// *************************************************************************** *
// *                                                                           *
// *                      Mentor Graphics Corporation                          *
// *                          All rights reserved                              *
// *                                                                           *
// *************************************************************************** *
// *                                                                           *
// * Description:         CANDB File                                           *
// * Generated at:        2021-02-26 13:32                                     *
// * System:              SPA4710_Final2                                       *
// * Variant:             ConfigurationsSPA3AD_prototype                       *
// * Network:             Mid6CANFD                                            *
// *                                                                           *
// *************************************************************************** *
// *                                                                           *
// *             THIS CONFIGURATION MIGHT CONTAIN SOME ERRORS                  *
// *              IF THE INPUT MODEL WAS NOT PROPERLY FORMED!                  *
// *                    Do Not Use this File directly!                         *
// *                                                                           *
// *************************************************************************** *
VERSION "Mid6CANFD"

NS_ :

BS_ :

BU_ :  ETC SSMB VIMB

BO_ 1292 SsmbMid6CanFdCanNmFr : 8 SSMB
 SG_ Body_SSMB : 21|1@0+ (1,0) [0|0] "" VIMB
 SG_ Brake_SSMB : 33|1@0+ (1,0) [0|0] "" VIMB
 SG_ Diesel_SSMB : 32|1@0+ (1,0) [0|0] "" VIMB
 SG_ Hazard_SSMB : 18|1@0+ (1,0) [0|0] "" VIMB
 SG_ InfotainmentAndHMI_SSMB : 22|1@0+ (1,0) [0|0] "" VIMB
 SG_ PNCCharging_SSMB : 25|1@0+ (1,0) [0|0] "" VIMB
 SG_ PNCDriverinfo_SSMB : 16|1@0+ (1,0) [0|0] "" VIMB
 SG_ PNCDriverinfoPoll_SSMB : 31|1@0+ (1,0) [0|0] "" VIMB
 SG_ PNCDriving_SSMB : 27|1@0+ (1,0) [0|0] "" VIMB
 SG_ PNCEntrance_SSMB : 23|1@0+ (1,0) [0|0] "" VIMB
 SG_ PNCGlobal_SSMB : 29|1@0+ (1,0) [0|0] "" VIMB
 SG_ PNCGSD_SSMB : 30|1@0+ (1,0) [0|0] "" VIMB
 SG_ PNCHVEnergyStorage_SSMB : 35|1@0+ (1,0) [0|0] "" VIMB
 SG_ PNCLocking_SSMB : 17|1@0+ (1,0) [0|0] "" VIMB
 SG_ PNCPreClimatization_SSMB : 26|1@0+ (1,0) [0|0] "" VIMB
 SG_ PNCSpare1_SSMB : 39|1@0+ (1,0) [0|0] "" VIMB
 SG_ PNCSpare2_SSMB : 38|1@0+ (1,0) [0|0] "" VIMB
 SG_ PNCSpare3_SSMB : 37|1@0+ (1,0) [0|0] "" VIMB
 SG_ PNCSpare4_SSMB : 36|1@0+ (1,0) [0|0] "" VIMB
 SG_ PNCStart_SSMB : 24|1@0+ (1,0) [0|0] "" VIMB
 SG_ PNCTrailerCaravan_SSMB : 28|1@0+ (1,0) [0|0] "" VIMB
 SG_ VehicleAPI_SSMB : 34|1@0+ (1,0) [0|0] "" VIMB
 SG_ Visibility_SSMB : 20|1@0+ (1,0) [0|0] "" VIMB
 SG_ WarningSounds_SSMB : 19|1@0+ (1,0) [0|0] "" VIMB
 SG_ NM_PNI_SSMB : 14|1@0+ (1,0) [0|0] "" VIMB
 SG_ NM_AW_SSMB : 12|1@0+ (1,0) [0|0] "" VIMB
 SG_ NM_CS_SSMB : 11|1@0+ (1,0) [0|0] "" VIMB
 SG_ NM_RMR_SSMB : 8|1@0+ (1,0) [0|0] "" VIMB
 SG_ NM_NodeID_SSMB : 7|8@0+ (1,0) [0|0] "" VIMB

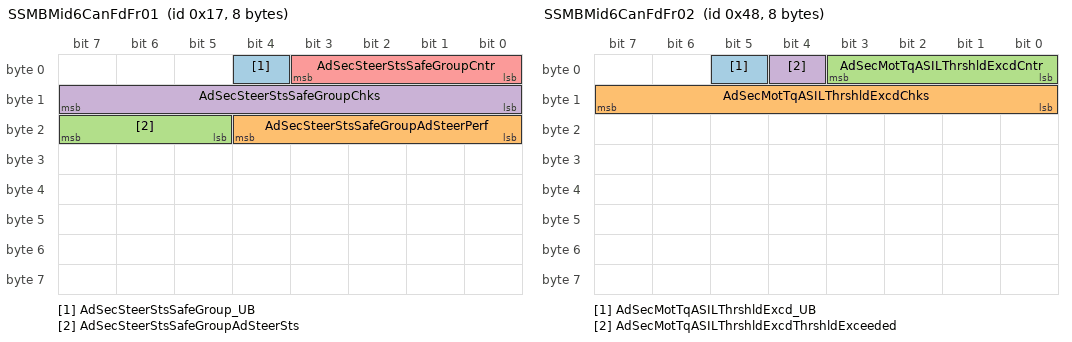
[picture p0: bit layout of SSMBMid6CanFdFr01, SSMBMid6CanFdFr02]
BO_ 23 SSMBMid6CanFdFr01 : 8 SSMB
 SG_ AdSecSteerStsSafeGroup_UB : 4|1@0+ (1,0) [0|1] "" VIMB
 SG_ AdSecSteerStsSafeGroupAdSteerPerf : 20|5@0+ (1,0) [0|31] "" VIMB
 SG_ AdSecSteerStsSafeGroupAdSteerSts : 23|3@0+ (1,0) [0|7] "" VIMB
 SG_ AdSecSteerStsSafeGroupChks : 15|8@0+ (1.0,0.0) [0.0|255.0] "Unitless" VIMB
 SG_ AdSecSteerStsSafeGroupCntr : 3|4@0+ (1.0,0.0) [0.0|15.0] "Unitless" VIMB

BO_ 72 SSMBMid6CanFdFr02 : 8 SSMB
 SG_ AdSecMotTqASILThrshldExcd_UB : 5|1@0+ (1,0) [0|1] "" VIMB
 SG_ AdSecMotTqASILThrshldExcdChks : 15|8@0+ (1.0,0.0) [0.0|255.0] "Unitless" VIMB
 SG_ AdSecMotTqASILThrshldExcdCntr : 3|4@0+ (1.0,0.0) [0.0|15.0] "Unitless" VIMB
 SG_ AdSecMotTqASILThrshldExcdThrshldExceeded : 4|1@0+ (1,0) [0|1] "" VIMB

BO_ 259 SSMBMid6CanFdFr03 : 16 SSMB
 SG_ SecPoseMonSafe_UB : 22|1@0+ (1,0) [0|1] "" VIMB
 SG_ SecPoseMonSafeChks : 31|8@0+ (1.0,0.0) [0.0|255.0] "Unitless" VIMB
 SG_ SecPoseMonSafeCntr : 19|4@0+ (1.0,0.0) [0.0|15.0] "Unitless" VIMB
 SG_ SecPoseMonSafeLatErr : 47|10@0- (0.005,0.0) [-2.56|2.555] "m" VIMB
 SG_ SecPoseMonSafeLgtErr : 53|11@0- (0.005,0.0) [-5.12|5.115] "m" VIMB
 SG_ SecPoseMonSafeSafeQf : 21|2@0+ (1,0) [0|3] "" VIMB
 SG_ SecPoseMonSafeYawErr : 39|8@0- (0.001,0.0) [-0.128|0.127] "rad" VIMB
 SG_ SecSteerMotTq_UB : 23|1@0+ (1,0) [0|1] "" VIMB
 SG_ SecSteerMotTqSteerMotTq : 5|14@0- (0.00390625,0.0) [-30.0|30.0] "NewtonMeter" VIMB
 SG_ SecSteerMotTqSteerMotTqQf : 7|2@0+ (1,0) [0|3] "" VIMB
 SG_ SecWhlLockSts_UB : 58|1@0+ (1,0) [0|1] "" VIMB
 SG_ SecWhlLockStsChks : 79|8@0+ (1.0,0.0) [0.0|255.0] "Unitless" VIMB
 SG_ SecWhlLockStsCntr : 67|4@0+ (1.0,0.0) [0.0|15.0] "Unitless" VIMB
 SG_ SecWhlLockStsDegradedSts : 57|2@0+ (1,0) [0|3] "" VIMB
 SG_ SecWhlLockStsLockSts : 70|3@0+ (1,0) [0|7] "" VIMB
 SG_ SSMBDegraded_UB : 103|1@0+ (1,0) [0|1] "" VIMB
 SG_ SSMBDegradedchks : 95|8@0+ (1.0,0.0) [0.0|255.0] "Unitless" VIMB
 SG_ SSMBDegradedcntr : 83|4@0+ (1.0,0.0) [0.0|15.0] "Unitless" VIMB
 SG_ SSMBDegradedSSMBDegraded : 87|4@0+ (1,0) [0|15] "" VIMB

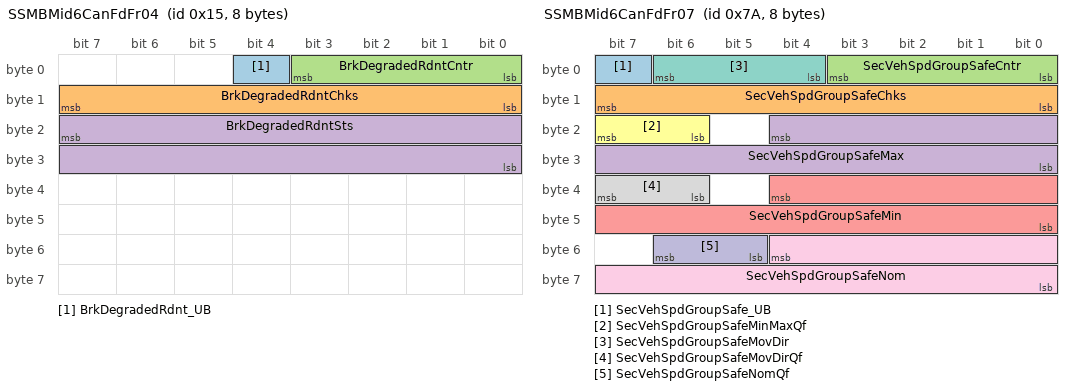
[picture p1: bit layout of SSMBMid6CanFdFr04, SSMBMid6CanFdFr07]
BO_ 21 SSMBMid6CanFdFr04 : 8 SSMB
 SG_ BrkDegradedRdnt_UB : 4|1@0+ (1,0) [0|1] "" VIMB
 SG_ BrkDegradedRdntChks : 15|8@0+ (1.0,0.0) [0.0|255.0] "Unitless" VIMB
 SG_ BrkDegradedRdntCntr : 3|4@0+ (1.0,0.0) [0.0|15.0] "Unitless" VIMB
 SG_ BrkDegradedRdntSts : 23|16@0+ (1.0,0.0) [0.0|65535.0] "Unitless" VIMB

BO_ 32 SSMBMid6CanFdFr05 : 16 SSMB
 SG_ AdSecWhlAgEstimdGroupSafe_UB : 4|1@0+ (1,0) [0|1] "" VIMB
 SG_ AdSecWhlAgEstimdGroupSafeChks : 15|8@0+ (1.0,0.0) [0.0|255.0] "Unitless" VIMB
 SG_ AdSecWhlAgEstimdGroupSafeCntr : 3|4@0+ (1.0,0.0) [0.0|15.0] "Unitless" VIMB
 SG_ AdSecWhlAgEstimdGroupSafeQf1 : 55|2@0+ (1,0) [0|3] "" VIMB
 SG_ AdSecWhlAgEstimdGroupSafeWhlAg : 22|15@0+ (0.00005249,-0.85) [-0.85|0.8500461200000001] "rad" VIMB
 SG_ AdSecWhlAgEstimdGroupSafeWhlAgRate : 38|15@0+ (0.00005,-0.7) [-0.7|0.7000000000000002] "rad/s" VIMB
 SG_ SecWhlRotToothCntr_UB : 52|1@0+ (1,0) [0|1] "" VIMB
 SG_ SecWhlRotToothCntrChks : 63|8@0+ (1.0,0.0) [0.0|255.0] "Unitless" VIMB
 SG_ SecWhlRotToothCntrCntr : 51|4@0+ (1.0,0.0) [0.0|15.0] "Unitless" VIMB
 SG_ SecWhlRotToothCntrWhlRotToothCntrFrntLe : 71|8@0+ (1.0,0.0) [0.0|255.0] "Unitless" VIMB
 SG_ SecWhlRotToothCntrWhlRotToothCntrFrntLeQf : 79|2@0+ (1,0) [0|3] "" VIMB
 SG_ SecWhlRotToothCntrWhlRotToothCntrFrntRi : 87|8@0+ (1.0,0.0) [0.0|255.0] "Unitless" VIMB
 SG_ SecWhlRotToothCntrWhlRotToothCntrFrntRiQf : 77|2@0+ (1,0) [0|3] "" VIMB
 SG_ SecWhlRotToothCntrWhlRotToothCntrReLe : 95|8@0+ (1.0,0.0) [0.0|255.0] "Unitless" VIMB
 SG_ SecWhlRotToothCntrWhlRotToothCntrReLeQf : 75|2@0+ (1,0) [0|3] "" VIMB
 SG_ SecWhlRotToothCntrWhlRotToothCntrReRi : 103|8@0+ (1.0,0.0) [0.0|255.0] "Unitless" VIMB
 SG_ SecWhlRotToothCntrWhlRotToothCntrReRiQf : 73|2@0+ (1,0) [0|3] "" VIMB

BO_ 49 SSMBMid6CanFdFr06 : 64 SSMB
 SG_ SecALatDataRawSafe_UB : 7|1@0+ (1,0) [0|1] "" VIMB
 SG_ SecALatDataRawSafeChks : 15|8@0+ (1.0,0.0) [0.0|255.0] "Unitless" VIMB
 SG_ SecALatDataRawSafeCntr : 3|4@0+ (1.0,0.0) [0.0|15.0] "Unitless" VIMB
 SG_ SecALatDataRawSafeMax : 23|15@0+ (0.001,-16.384) [-16.384|16.383000000000003] "m/s^2" VIMB
 SG_ SecALatDataRawSafeMin : 39|15@0+ (0.001,-16.384) [-16.384|16.383000000000003] "m/s^2" VIMB
 SG_ SecALatDataRawSafeMinMaxQf : 6|2@0+ (1,0) [0|3] "" VIMB
 SG_ SecALatDataRawSafeNom : 55|15@0+ (0.001,-16.384) [-16.384|16.383000000000003] "m/s^2" VIMB
 SG_ SecALatDataRawSafeNomQf : 71|2@0+ (1,0) [0|3] "" VIMB
 SG_ SecALgtDataRawSafe_UB : 196|1@0+ (1,0) [0|1] "" VIMB
 SG_ SecALgtDataRawSafeChks : 79|8@0+ (1.0,0.0) [0.0|255.0] "Unitless" VIMB
 SG_ SecALgtDataRawSafeCntr : 67|4@0+ (1.0,0.0) [0.0|15.0] "Unitless" VIMB
 SG_ SecALgtDataRawSafeMax : 86|15@0+ (0.001,-16.384) [-16.384|16.383000000000003] "m/s^2" VIMB
 SG_ SecALgtDataRawSafeMin : 102|15@0+ (0.001,-16.384) [-16.384|16.383000000000003] "m/s^2" VIMB
 SG_ SecALgtDataRawSafeMinMaxQf : 135|2@0+ (1,0) [0|3] "" VIMB
 SG_ SecALgtDataRawSafeNom : 118|15@0+ (0.001,-16.384) [-16.384|16.383000000000003] "m/s^2" VIMB
 SG_ SecALgtDataRawSafeNomQf : 69|2@0+ (1,0) [0|3] "" VIMB
 SG_ SecAxleSlipStsAndRelAg_UB : 199|1@0+ (1,0) [0|1] "" VIMB
 SG_ SecAxleSlipStsAndRelAgFrntAxle : 223|2@0+ (1,0) [0|3] "" VIMB
 SG_ SecAxleSlipStsAndRelAgIntvSts : 263|2@0+ (1,0) [0|3] "" VIMB
 SG_ SecAxleSlipStsAndRelAgReAxle : 221|2@0+ (1,0) [0|3] "" VIMB
 SG_ SecAxleSlipStsAndRelAgRelPitch : 231|16@0- (0.00005,0.0) [-1.6384|1.6383] "rad" VIMB
 SG_ SecAxleSlipStsAndRelAgRelPitchQf : 219|2@0+ (1,0) [0|3] "" VIMB
 SG_ SecAxleSlipStsAndRelAgRelRoll : 247|16@0- (0.00005,0.0) [-1.6384|1.6383] "rad" VIMB
 SG_ SecAxleSlipStsAndRelAgRelRolQf : 217|2@0+ (1,0) [0|3] "" VIMB
 SG_ SecVLatSafe_UB : 260|1@0+ (1,0) [0|1] "" VIMB
 SG_ SecVLatSafeChks : 279|8@0+ (1.0,0.0) [0.0|255.0] "Unitless" VIMB
 SG_ SecVLatSafeCntr : 259|4@0+ (1.0,0.0) [0.0|15.0] "Unitless" VIMB
 SG_ SecVLatSafeMax : 286|15@0- (0.001,0.0) [-16.384|16.383] "m/s" VIMB
 SG_ SecVLatSafeMin : 302|15@0- (0.001,0.0) [-16.384|16.383] "m/s" VIMB
 SG_ SecVLatSafeMinMaxQf : 266|2@0+ (1,0) [0|3] "" VIMB
 SG_ SecVLatSafeNom : 318|15@0- (0.001,0.0) [-16.384|16.383] "m/s" VIMB
 SG_ SecVLatSafeNomQf : 268|2@0+ (1,0) [0|3] "" VIMB
 SG_ SecWhlRotDirReSafe_UB : 198|1@0+ (1,0) [0|1] "" VIMB
 SG_ SecWhlRotDirReSafeChks : 215|8@0+ (1.0,0.0) [0.0|255.0] "Unitless" VIMB
 SG_ SecWhlRotDirReSafeCntr : 195|4@0+ (1.0,0.0) [0.0|15.0] "Unitless" VIMB
 SG_ SecWhlRotDirReSafeLe : 207|2@0+ (1,0) [0|3] "" VIMB
 SG_ SecWhlRotDirReSafeLeQf : 205|2@0+ (1,0) [0|3] "" VIMB
 SG_ SecWhlRotDirReSafeRi : 203|2@0+ (1,0) [0|3] "" VIMB
 SG_ SecWhlRotDirReSafeRiQf : 201|2@0+ (1,0) [0|3] "" VIMB
 SG_ SecYawRateSafe_UB : 330|1@0+ (1,0) [0|1] "" VIMB
 SG_ SecYawRateSafeChks : 351|8@0+ (1.0,0.0) [0.0|255.0] "Unitless" VIMB
 SG_ SecYawRateSafeCntr : 339|4@0+ (1.0,0.0) [0.0|15.0] "Unitless" VIMB
 SG_ SecYawRateSafeMax : 358|15@0- (0.0002,0.0) [-3.2768|3.2766] "rad/s" VIMB
 SG_ SecYawRateSafeMin : 374|15@0- (0.0002,0.0) [-3.2768|3.2766] "rad/s" VIMB
 SG_ SecYawRateSafeMinMaxQf : 342|2@0+ (1,0) [0|3] "" VIMB
 SG_ SecYawRateSafeNom : 390|15@0- (0.0002,0.0) [-3.2768|3.2766] "rad/s" VIMB
 SG_ SecYawRateSafeNomQf : 329|2@0+ (1,0) [0|3] "" VIMB

BO_ 122 SSMBMid6CanFdFr07 : 8 SSMB
 SG_ SecVehSpdGroupSafe_UB : 7|1@0+ (1,0) [0|1] "" VIMB
 SG_ SecVehSpdGroupSafeChks : 15|8@0+ (1.0,0.0) [0.0|255.0] "Unitless" VIMB
 SG_ SecVehSpdGroupSafeCntr : 3|4@0+ (1.0,0.0) [0.0|15.0] "Unitless" VIMB
 SG_ SecVehSpdGroupSafeMax : 20|13@0+ (0.01,0.0) [0.0|81.91] "m/s" VIMB
 SG_ SecVehSpdGroupSafeMin : 36|13@0+ (0.01,0.0) [0.0|81.91] "m/s" VIMB
 SG_ SecVehSpdGroupSafeMinMaxQf : 23|2@0+ (1,0) [0|3] "" VIMB
 SG_ SecVehSpdGroupSafeMovDir : 6|3@0+ (1,0) [0|7] "" VIMB
 SG_ SecVehSpdGroupSafeMovDirQf : 39|2@0+ (1,0) [0|3] "" VIMB
 SG_ SecVehSpdGroupSafeNom : 52|13@0+ (0.01,0.0) [0.0|81.91] "m/s" VIMB
 SG_ SecVehSpdGroupSafeNomQf : 54|2@0+ (1,0) [0|3] "" VIMB

BO_ 52 SSMBMid6CanFdFr08 : 20 SSMB
 SG_ SecVehMSafe_UB : 141|1@0+ (1,0) [0|1] "" VIMB
 SG_ SecVehMSafeChks : 135|8@0+ (1.0,0.0) [0.0|255.0] "Unitless" VIMB
 SG_ SecVehMSafeCntr : 99|4@0+ (1.0,0.0) [0.0|15.0] "Unitless" VIMB
 SG_ SecVehMSafeNomQf : 101|2@0+ (1,0) [0|3] "" VIMB
 SG_ SecVehMSafeSafeQf : 143|2@0+ (1,0) [0|3] "" VIMB
 SG_ SecVehMSafeVehMMax : 111|8@0+ (5.0,2400.0) [2400.0|3675.0] "kg" VIMB
 SG_ SecVehMSafeVehMMin : 119|8@0+ (5.0,2400.0) [2400.0|3675.0] "kg" VIMB
 SG_ SecVehMSafeVehMNom : 127|8@0+ (5.0,2400.0) [2400.0|3675.0] "kg" VIMB
 SG_ SecWhlAgSpdFrntSafe_UB : 103|1@0+ (1,0) [0|1] "" VIMB
 SG_ SecWhlAgSpdFrntSafeChks : 15|8@0+ (1.0,0.0) [0.0|255.0] "Unitless" VIMB
 SG_ SecWhlAgSpdFrntSafeCntr : 3|4@0+ (1.0,0.0) [0.0|15.0] "Unitless" VIMB
 SG_ SecWhlAgSpdFrntSafeLe : 23|16@0- (0.0078125,0.0) [-255.0|255.0] "rad/s" VIMB
 SG_ SecWhlAgSpdFrntSafeLeQf : 5|2@0+ (1,0) [0|3] "" VIMB
 SG_ SecWhlAgSpdFrntSafeRi : 39|16@0- (0.0078125,0.0) [-255.0|255.0] "rad/s" VIMB
 SG_ SecWhlAgSpdFrntSafeRiQf : 7|2@0+ (1,0) [0|3] "" VIMB
 SG_ SecWhlAgSpdReSafe_UB : 102|1@0+ (1,0) [0|1] "" VIMB
 SG_ SecWhlAgSpdReSafeChks : 63|8@0+ (1.0,0.0) [0.0|255.0] "Unitless" VIMB
 SG_ SecWhlAgSpdReSafeCntr : 51|4@0+ (1.0,0.0) [0.0|15.0] "Unitless" VIMB
 SG_ SecWhlAgSpdReSafeLe : 71|16@0- (0.0078125,0.0) [-255.0|255.0] "rad/s" VIMB
 SG_ SecWhlAgSpdReSafeLeQf : 53|2@0+ (1,0) [0|3] "" VIMB
 SG_ SecWhlAgSpdReSafeRi : 87|16@0- (0.0078125,0.0) [-255.0|255.0] "rad/s" VIMB
 SG_ SecWhlAgSpdReSafeRiQf : 55|2@0+ (1,0) [0|3] "" VIMB

BO_ 85 SSMBMid6CanFdFr11 : 20 SSMB
 SG_ AdSecSafeStopActvGroupSafe_UB : 21|1@0+ (1,0) [0|1] "" VIMB
 SG_ AdSecSafeStopActvGroupSafeChks : 31|8@0+ (1.0,0.0) [0.0|255.0] "Unitless" VIMB
 SG_ AdSecSafeStopActvGroupSafeCntr : 19|4@0+ (1.0,0.0) [0.0|15.0] "Unitless" VIMB
 SG_ AdSecSafeStopActvGroupSafePlatformSafeStopActv : 20|1@0+ (1,0) [0|1] "" VIMB
 SG_ AdSecWhlAgRateLimEstimdSafe_UB : 22|1@0+ (1,0) [0|1] "" VIMB
 SG_ AdSecWhlAgRateLimEstimdSafeAdWhlAgRate1 : 86|15@0+ (0.00005,-0.7) [-0.7|0.7000000000000002] "rad/s" VIMB
 SG_ AdSecWhlAgRateLimEstimdSafeChks : 79|8@0+ (1.0,0.0) [0.0|255.0] "Unitless" VIMB
 SG_ AdSecWhlAgRateLimEstimdSafeCntr : 67|4@0+ (1.0,0.0) [0.0|15.0] "Unitless" VIMB
 SG_ SecMaxALatEstimdGroup_UB : 39|1@0+ (1,0) [0|1] "" VIMB
 SG_ SecMaxALatEstimdGroupAcceleration : 38|15@0- (0.0085,0.0) [-138.99200000000002|139.00050000000002] "m/s^2" VIMB
 SG_ SecMaxALatEstimdGroupJerk : 54|15@0- (0.000244140625,0.0) [-4.0|3.999755859375] "Unitless" VIMB

BO_ 1290 VimbMid6CanFdCanNmFr : 8 VIMB
 SG_ Body_VIMB : 21|1@0+ (1,0) [0|0] "" SSMB
 SG_ Brake_VIMB : 33|1@0+ (1,0) [0|0] "" SSMB
 SG_ Diesel_VIMB : 32|1@0+ (1,0) [0|0] "" SSMB
 SG_ Hazard_VIMB : 18|1@0+ (1,0) [0|0] "" SSMB
 SG_ InfotainmentAndHMI_VIMB : 22|1@0+ (1,0) [0|0] "" SSMB
 SG_ PNCCharging_VIMB : 25|1@0+ (1,0) [0|0] "" SSMB
 SG_ PNCDriverinfo_VIMB : 16|1@0+ (1,0) [0|0] "" SSMB
 SG_ PNCDriverinfoPoll_VIMB : 31|1@0+ (1,0) [0|0] "" SSMB
 SG_ PNCDriving_VIMB : 27|1@0+ (1,0) [0|0] "" SSMB
 SG_ PNCEntrance_VIMB : 23|1@0+ (1,0) [0|0] "" SSMB
 SG_ PNCGlobal_VIMB : 29|1@0+ (1,0) [0|0] "" SSMB
 SG_ PNCGSD_VIMB : 30|1@0+ (1,0) [0|0] "" SSMB
 SG_ PNCHVEnergyStorage_VIMB : 35|1@0+ (1,0) [0|0] "" SSMB
 SG_ PNCLocking_VIMB : 17|1@0+ (1,0) [0|0] "" SSMB
 SG_ PNCPreClimatization_VIMB : 26|1@0+ (1,0) [0|0] "" SSMB
 SG_ PNCSpare1_VIMB : 39|1@0+ (1,0) [0|0] "" SSMB
 SG_ PNCSpare2_VIMB : 38|1@0+ (1,0) [0|0] "" SSMB
 SG_ PNCSpare3_VIMB : 37|1@0+ (1,0) [0|0] "" SSMB
 SG_ PNCSpare4_VIMB : 36|1@0+ (1,0) [0|0] "" SSMB
 SG_ PNCStart_VIMB : 24|1@0+ (1,0) [0|0] "" SSMB
 SG_ PNCTrailerCaravan_VIMB : 28|1@0+ (1,0) [0|0] "" SSMB
 SG_ VehicleAPI_VIMB : 34|1@0+ (1,0) [0|0] "" SSMB
 SG_ Visibility_VIMB : 20|1@0+ (1,0) [0|0] "" SSMB
 SG_ WarningSounds_VIMB : 19|1@0+ (1,0) [0|0] "" SSMB
 SG_ NM_PNI_VIMB : 14|1@0+ (1,0) [0|0] "" SSMB
 SG_ NM_AW_VIMB : 12|1@0+ (1,0) [0|0] "" SSMB
 SG_ NM_CS_VIMB : 11|1@0+ (1,0) [0|0] "" SSMB
 SG_ NM_RMR_VIMB : 8|1@0+ (1,0) [0|0] "" SSMB
 SG_ NM_NodeID_VIMB : 7|8@0+ (1,0) [0|0] "" SSMB

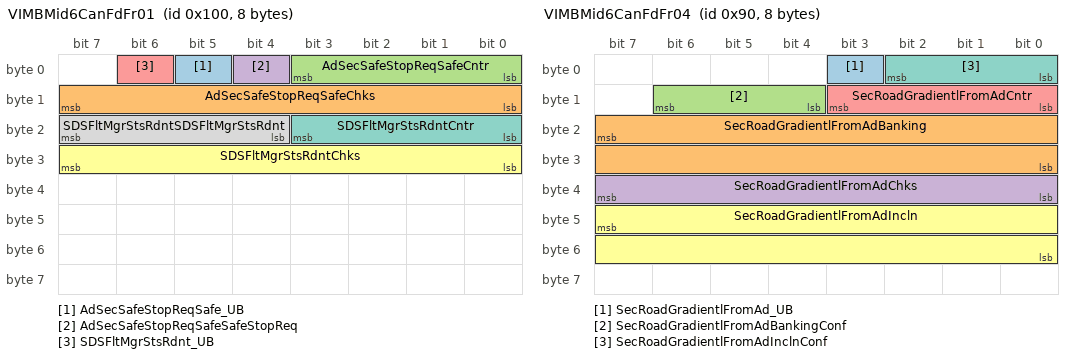
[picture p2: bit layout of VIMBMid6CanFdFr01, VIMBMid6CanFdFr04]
BO_ 256 VIMBMid6CanFdFr01 : 8 VIMB
 SG_ AdSecSafeStopReqSafe_UB : 5|1@0+ (1,0) [0|1] "" SSMB
 SG_ AdSecSafeStopReqSafeChks : 15|8@0+ (1.0,0.0) [0.0|255.0] "Unitless" SSMB
 SG_ AdSecSafeStopReqSafeCntr : 3|4@0+ (1.0,0.0) [0.0|15.0] "Unitless" SSMB
 SG_ AdSecSafeStopReqSafeSafeStopReq : 4|1@0+ (1,0) [0|1] "" SSMB
 SG_ SDSFltMgrStsRdnt_UB : 6|1@0+ (1,0) [0|1] "" SSMB
 SG_ SDSFltMgrStsRdntChks : 31|8@0+ (1.0,0.0) [0.0|255.0] "Unitless" SSMB
 SG_ SDSFltMgrStsRdntCntr : 19|4@0+ (1.0,0.0) [0.0|15.0] "Unitless" SSMB
 SG_ SDSFltMgrStsRdntSDSFltMgrStsRdnt : 23|4@0+ (1,0) [0|15] "" SSMB

BO_ 65 VIMBMid6CanFdFr03 : 64 VIMB
 SG_ AdSecPose_UB : 511|1@0+ (1,0) [0|1] "" SSMB
 SG_ AdSecPoseAX : 24|20@1+ (0.0001,-52.429) [-52.429|52.4285] "m/s^2" SSMB
 SG_ AdSecPoseAXConf : 400|3@1+ (1.0,0.0) [0.0|7.0] "Unitless" SSMB
 SG_ AdSecPoseAY : 48|20@1+ (0.0001,-52.429) [-52.429|52.4285] "m/s^2" SSMB
 SG_ AdSecPoseAYConf : 408|3@1+ (1.0,0.0) [0.0|7.0] "Unitless" SSMB
 SG_ AdSecPoseAZ : 72|20@1+ (0.0001,-52.429) [-52.429|52.4285] "m/s^2" SSMB
 SG_ AdSecPoseAZConf : 416|3@1+ (1.0,0.0) [0.0|7.0] "Unitless" SSMB
 SG_ AdSecPoseChks : 0|16@1+ (1.0,0.0) [0.0|65535.0] "Unitless" SSMB
 SG_ AdSecPoseCntr : 16|8@1+ (1.0,0.0) [0.0|255.0] "Unitless" SSMB
 SG_ AdSecPoseDataID : 96|16@1+ (1.0,0.0) [0.0|65535.0] "Unitless" SSMB
 SG_ AdSecPosePitch : 112|16@1+ (0.00005,-1.638) [-1.638|1.6380000000000003] "rad" SSMB
 SG_ AdSecPosePitchConf : 424|3@1+ (1.0,0.0) [0.0|7.0] "Unitless" SSMB
 SG_ AdSecPosePitchRate : 128|20@1+ (0.00001,-5.243) [-5.243|5.242750000000001] "rad/s" SSMB
 SG_ AdSecPosePitchRateConf : 432|3@1+ (1.0,0.0) [0.0|7.0] "Unitless" SSMB
 SG_ AdSecPosePosX : 152|32@1- (1.0,0.0) [-2147483648.0|2147483647.0] "5mm" SSMB
 SG_ AdSecPosePosXConf : 440|3@1+ (1.0,0.0) [0.0|7.0] "Unitless" SSMB
 SG_ AdSecPosePosY : 184|32@1- (1.0,0.0) [-2147483648.0|2147483647.0] "5mm" SSMB
 SG_ AdSecPosePosYConf : 448|3@1+ (1.0,0.0) [0.0|7.0] "Unitless" SSMB
 SG_ AdSecPoseRoll : 216|16@1+ (0.00005,-1.638) [-1.638|1.6380000000000003] "rad" SSMB
 SG_ AdSecPoseRollConf : 456|3@1+ (1.0,0.0) [0.0|7.0] "Unitless" SSMB
 SG_ AdSecPoseRollRate : 232|20@1+ (0.00001,-5.243) [-5.243|5.242750000000001] "rad/s" SSMB
 SG_ AdSecPoseRollRateConf : 464|3@1+ (1.0,0.0) [0.0|7.0] "Unitless" SSMB
 SG_ AdSecPoseTiStampNanoSec : 256|32@1+ (1.0,0.0) [0.0|4294967295.0] "ns" SSMB
 SG_ AdSecPoseTiStampSec : 288|32@1+ (1.0,0.0) [0.0|4294967295.0] "s" SSMB
 SG_ AdSecPoseVX : 320|16@1+ (0.001,-12.768) [-12.768|52.766999999999996] "m/s" SSMB
 SG_ AdSecPoseVXConf : 472|3@1+ (1.0,0.0) [0.0|7.0] "Unitless" SSMB
 SG_ AdSecPoseVY : 336|14@1+ (0.001,-8.192) [-8.192|8.190999999999999] "m/s" SSMB
 SG_ AdSecPoseVYConf : 480|3@1+ (1.0,0.0) [0.0|7.0] "Unitless" SSMB
 SG_ AdSecPoseYaw : 352|24@1+ (0.0000005,-4.194) [-4.194|4.194] "rad" SSMB
 SG_ AdSecPoseYawConf : 488|3@1+ (1.0,0.0) [0.0|7.0] "Unitless" SSMB
 SG_ AdSecPoseYawRate : 376|22@1+ (0.000001,-2.097) [-2.097|2.097] "rad/s" SSMB
 SG_ AdSecPoseYawRateConf : 496|3@1+ (1.0,0.0) [0.0|7.0] "Unitless" SSMB

BO_ 144 VIMBMid6CanFdFr04 : 8 VIMB
 SG_ SecRoadGradientlFromAd_UB : 3|1@0+ (1,0) [0|1] "" SSMB
 SG_ SecRoadGradientlFromAdBanking : 23|16@0- (0.000030518,0.0) [-0.9999833060000001|0.9999833060000001] "rad" SSMB
 SG_ SecRoadGradientlFromAdBankingConf : 14|3@0+ (1,0) [0|7] "" SSMB
 SG_ SecRoadGradientlFromAdChks : 39|8@0+ (1.0,0.0) [0.0|255.0] "Unitless" SSMB
 SG_ SecRoadGradientlFromAdCntr : 11|4@0+ (1.0,0.0) [0.0|15.0] "Unitless" SSMB
 SG_ SecRoadGradientlFromAdIncln : 47|16@0- (0.000030518,0.0) [-0.9999833060000001|0.9999833060000001] "rad" SSMB
 SG_ SecRoadGradientlFromAdInclnConf : 2|3@0+ (1,0) [0|7] "" SSMB

BO_ 38 VIMBMid6CanFdFr14 : 16 VIMB
 SG_ AdSecWhlAgReqGroupSafe_UB : 4|1@0+ (1,0) [0|1] "" SSMB
 SG_ AdSecWhlAgReqGroupSafeChks : 31|8@0+ (1.0,0.0) [0.0|255.0] "Unitless" SSMB
 SG_ AdSecWhlAgReqGroupSafeCntr : 3|4@0+ (1.0,0.0) [0.0|15.0] "Unitless" SSMB
 SG_ AdSecWhlAgReqGroupSafeWhlAgReq : 14|15@0+ (0.00005249,-0.85) [-0.85|0.8500461200000001] "rad" SSMB

BO_ 272 VIMBMid6CanFdFr19 : 48 VIMB
 SG_ AdSecPSSGroupSafe0_UB : 383|1@0+ (1,0) [0|1] "" SSMB
 SG_ AdSecPSSGroupSafe0Chks : 0|16@1+ (1.0,0.0) [0.0|65535.0] "Unitless" SSMB
 SG_ AdSecPSSGroupSafe0Cntr : 16|8@1+ (1.0,0.0) [0.0|255.0] "Unitless" SSMB
 SG_ AdSecPSSGroupSafe0DataID : 24|16@1+ (1.0,0.0) [0.0|65535.0] "Unitless" SSMB
 SG_ AdSecPSSGroupSafe0DeltaTPos1 : 48|18@1+ (0.000001,0.0) [0.0|0.262] "s" SSMB
 SG_ AdSecPSSGroupSafe0DeltaTPos2 : 72|18@1+ (0.000001,0.0) [0.0|0.262] "s" SSMB
 SG_ AdSecPSSGroupSafe0DeltaXPos1 : 96|18@1+ (0.0001,-13.107) [-13.107|13.107000000000003] "m" SSMB
 SG_ AdSecPSSGroupSafe0DeltaXPos2 : 120|18@1+ (0.0001,-13.107) [-13.107|13.107000000000003] "m" SSMB
 SG_ AdSecPSSGroupSafe0DeltaYPos1 : 144|18@1+ (0.0001,-13.107) [-13.107|13.107000000000003] "m" SSMB
 SG_ AdSecPSSGroupSafe0DeltaYPos2 : 168|18@1+ (0.0001,-13.107) [-13.107|13.107000000000003] "m" SSMB
 SG_ AdSecPSSGroupSafe0HeadingPos1 : 192|16@1+ (0.0001,-3.2767) [-3.2767|3.2768000000000006] "rad" SSMB
 SG_ AdSecPSSGroupSafe0HeadingPos2 : 208|16@1+ (0.0001,-3.2767) [-3.2767|3.2768000000000006] "rad" SSMB
 SG_ AdSecPSSGroupSafe0InitHeading : 224|16@1+ (0.0001,-3.2767) [-3.2767|3.2768000000000006] "rad" SSMB
 SG_ AdSecPSSGroupSafe0InitPosX : 240|32@1- (1.0,0.0) [-2147483648.0|2147483647.0] "m" SSMB
 SG_ AdSecPSSGroupSafe0InitPosY : 272|32@1- (1.0,0.0) [-2147483648.0|2147483647.0] "m" SSMB
 SG_ AdSecPSSGroupSafe0TiStampNanoSec : 304|32@1+ (1.0,0.0) [0.0|4294967295.0] "Unitless" SSMB
 SG_ AdSecPSSGroupSafe0TiStampSec : 336|32@1+ (1.0,0.0) [0.0|4294967295.0] "Unitless" SSMB
 SG_ AdSecPSSGroupSafe0TrajectID : 368|4@1+ (1.0,0.0) [0.0|15.0] "Unitless" SSMB

BO_ 278 VIMBMid6CanFdFr20 : 64 VIMB
 SG_ AdSecPSSGroupSafe1_UB : 511|1@0+ (1,0) [0|1] "" SSMB
 SG_ AdSecPSSGroupSafe1Chks : 0|16@1+ (1.0,0.0) [0.0|65535.0] "Unitless" SSMB
 SG_ AdSecPSSGroupSafe1Cntr : 16|8@1+ (1.0,0.0) [0.0|255.0] "Unitless" SSMB
 SG_ AdSecPSSGroupSafe1DataID : 24|16@1+ (1.0,0.0) [0.0|65535.0] "Unitless" SSMB
 SG_ AdSecPSSGroupSafe1DeltaTPos1 : 40|18@1+ (0.000001,0.0) [0.0|0.262] "s" SSMB
 SG_ AdSecPSSGroupSafe1DeltaTPos2 : 64|18@1+ (0.000001,0.0) [0.0|0.262] "s" SSMB
 SG_ AdSecPSSGroupSafe1DeltaTPos3 : 88|18@1+ (0.000001,0.0) [0.0|0.262] "s" SSMB
 SG_ AdSecPSSGroupSafe1DeltaTPos4 : 112|18@1+ (0.000001,0.0) [0.0|0.262] "s" SSMB
 SG_ AdSecPSSGroupSafe1DeltaTPos5 : 136|18@1+ (0.000001,0.0) [0.0|0.262] "s" SSMB
 SG_ AdSecPSSGroupSafe1DeltaTPos6 : 160|18@1+ (0.000001,0.0) [0.0|0.262] "s" SSMB
 SG_ AdSecPSSGroupSafe1DeltaXPos1 : 184|18@1+ (0.0001,-13.107) [-13.107|13.107000000000003] "m" SSMB
 SG_ AdSecPSSGroupSafe1DeltaXPos2 : 202|18@1+ (0.0001,-13.107) [-13.107|13.107000000000003] "m" SSMB
 SG_ AdSecPSSGroupSafe1DeltaXPos3 : 220|18@1+ (0.0001,-13.107) [-13.107|13.107000000000003] "m" SSMB
 SG_ AdSecPSSGroupSafe1DeltaXPos4 : 238|18@1+ (0.0001,-13.107) [-13.107|13.107000000000003] "m" SSMB
 SG_ AdSecPSSGroupSafe1DeltaXPos5 : 256|18@1+ (0.0001,-13.107) [-13.107|13.107000000000003] "m" SSMB
 SG_ AdSecPSSGroupSafe1DeltaXPos6 : 274|18@1+ (0.0001,-13.107) [-13.107|13.107000000000003] "m" SSMB
 SG_ AdSecPSSGroupSafe1DeltaYPos1 : 292|18@1+ (0.0001,-13.107) [-13.107|13.107000000000003] "m" SSMB
 SG_ AdSecPSSGroupSafe1DeltaYPos2 : 310|18@1+ (0.0001,-13.107) [-13.107|13.107000000000003] "m" SSMB
 SG_ AdSecPSSGroupSafe1DeltaYPos3 : 328|18@1+ (0.0001,-13.107) [-13.107|13.107000000000003] "m" SSMB
 SG_ AdSecPSSGroupSafe1DeltaYPos4 : 346|18@1+ (0.0001,-13.107) [-13.107|13.107000000000003] "m" SSMB
 SG_ AdSecPSSGroupSafe1DeltaYPos5 : 364|18@1+ (0.0001,-13.107) [-13.107|13.107000000000003] "m" SSMB
 SG_ AdSecPSSGroupSafe1DeltaYPos6 : 382|18@1+ (0.0001,-13.107) [-13.107|13.107000000000003] "m" SSMB
 SG_ AdSecPSSGroupSafe1HeadingPos1 : 400|16@1+ (0.0001,-3.2767) [-3.2767|3.2768000000000006] "rad" SSMB
 SG_ AdSecPSSGroupSafe1HeadingPos2 : 416|16@1+ (0.0001,-3.2767) [-3.2767|3.2768000000000006] "rad" SSMB
 SG_ AdSecPSSGroupSafe1HeadingPos3 : 432|16@1+ (0.0001,-3.2767) [-3.2767|3.2768000000000006] "rad" SSMB
 SG_ AdSecPSSGroupSafe1HeadingPos4 : 448|16@1+ (0.0001,-3.2767) [-3.2767|3.2768000000000006] "rad" SSMB
 SG_ AdSecPSSGroupSafe1HeadingPos5 : 464|16@1+ (0.0001,-3.2767) [-3.2767|3.2768000000000006] "rad" SSMB
 SG_ AdSecPSSGroupSafe1HeadingPos6 : 480|16@1+ (0.0001,-3.2767) [-3.2767|3.2768000000000006] "rad" SSMB
 SG_ AdSecPSSGroupSafe1TrajectID : 496|4@1+ (1.0,0.0) [0.0|15.0] "Unitless" SSMB

BO_ 281 VIMBMid6CanFdFr21 : 64 VIMB
 SG_ AdSecPSSGroupSafe2_UB : 511|1@0+ (1,0) [0|1] "" SSMB
 SG_ AdSecPSSGroupSafe2Chks : 0|16@1+ (1.0,0.0) [0.0|65535.0] "Unitless" SSMB
 SG_ AdSecPSSGroupSafe2Cntr : 16|8@1+ (1.0,0.0) [0.0|255.0] "Unitless" SSMB
 SG_ AdSecPSSGroupSafe2DataID : 24|16@1+ (1.0,0.0) [0.0|65535.0] "Unitless" SSMB
 SG_ AdSecPSSGroupSafe2DeltaTPos1 : 40|18@1+ (0.000001,0.0) [0.0|0.262] "s" SSMB
 SG_ AdSecPSSGroupSafe2DeltaTPos2 : 64|18@1+ (0.000001,0.0) [0.0|0.262] "s" SSMB
 SG_ AdSecPSSGroupSafe2DeltaTPos3 : 88|18@1+ (0.000001,0.0) [0.0|0.262] "s" SSMB
 SG_ AdSecPSSGroupSafe2DeltaTPos4 : 112|18@1+ (0.000001,0.0) [0.0|0.262] "s" SSMB
 SG_ AdSecPSSGroupSafe2DeltaTPos5 : 136|18@1+ (0.000001,0.0) [0.0|0.262] "s" SSMB
 SG_ AdSecPSSGroupSafe2DeltaTPos6 : 160|18@1+ (0.000001,0.0) [0.0|0.262] "s" SSMB
 SG_ AdSecPSSGroupSafe2DeltaXPos1 : 184|18@1+ (0.0001,-13.107) [-13.107|13.107000000000003] "m" SSMB
 SG_ AdSecPSSGroupSafe2DeltaXPos2 : 202|18@1+ (0.0001,-13.107) [-13.107|13.107000000000003] "m" SSMB
 SG_ AdSecPSSGroupSafe2DeltaXPos3 : 220|18@1+ (0.0001,-13.107) [-13.107|13.107000000000003] "m" SSMB
 SG_ AdSecPSSGroupSafe2DeltaXPos4 : 238|18@1+ (0.0001,-13.107) [-13.107|13.107000000000003] "m" SSMB
 SG_ AdSecPSSGroupSafe2DeltaXPos5 : 256|18@1+ (0.0001,-13.107) [-13.107|13.107000000000003] "m" SSMB
 SG_ AdSecPSSGroupSafe2DeltaXPos6 : 274|18@1+ (0.0001,-13.107) [-13.107|13.107000000000003] "m" SSMB
 SG_ AdSecPSSGroupSafe2DeltaYPos1 : 292|18@1+ (0.0001,-13.107) [-13.107|13.107000000000003] "m" SSMB
 SG_ AdSecPSSGroupSafe2DeltaYPos2 : 310|18@1+ (0.0001,-13.107) [-13.107|13.107000000000003] "m" SSMB
 SG_ AdSecPSSGroupSafe2DeltaYPos3 : 328|18@1+ (0.0001,-13.107) [-13.107|13.107000000000003] "m" SSMB
 SG_ AdSecPSSGroupSafe2DeltaYPos4 : 346|18@1+ (0.0001,-13.107) [-13.107|13.107000000000003] "m" SSMB
 SG_ AdSecPSSGroupSafe2DeltaYPos5 : 364|18@1+ (0.0001,-13.107) [-13.107|13.107000000000003] "m" SSMB
 SG_ AdSecPSSGroupSafe2DeltaYPos6 : 382|18@1+ (0.0001,-13.107) [-13.107|13.107000000000003] "m" SSMB
 SG_ AdSecPSSGroupSafe2HeadingPos1 : 400|16@1+ (0.0001,-3.2767) [-3.2767|3.2768000000000006] "rad" SSMB
 SG_ AdSecPSSGroupSafe2HeadingPos2 : 416|16@1+ (0.0001,-3.2767) [-3.2767|3.2768000000000006] "rad" SSMB
 SG_ AdSecPSSGroupSafe2HeadingPos3 : 432|16@1+ (0.0001,-3.2767) [-3.2767|3.2768000000000006] "rad" SSMB
 SG_ AdSecPSSGroupSafe2HeadingPos4 : 448|16@1+ (0.0001,-3.2767) [-3.2767|3.2768000000000006] "rad" SSMB
 SG_ AdSecPSSGroupSafe2HeadingPos5 : 464|16@1+ (0.0001,-3.2767) [-3.2767|3.2768000000000006] "rad" SSMB
 SG_ AdSecPSSGroupSafe2HeadingPos6 : 480|16@1+ (0.0001,-3.2767) [-3.2767|3.2768000000000006] "rad" SSMB
 SG_ AdSecPSSGroupSafe2TrajectID : 496|4@1+ (1.0,0.0) [0.0|15.0] "Unitless" SSMB

// Node Comments
CM_ BU_ ETC "External Tester Connector";

// Signal Comments
CM_ SG_ 23 AdSecSteerStsSafeGroupAdSteerPerf " Performance of MotorHalf1 + MotorHalf2";
CM_ SG_ 23 AdSecSteerStsSafeGroupAdSteerSts " Status of steering system";
CM_ SG_ 23 AdSecSteerStsSafeGroupChks " E2E-protection";
CM_ SG_ 23 AdSecSteerStsSafeGroupCntr " E2E-protection";
CM_ SG_ 72 AdSecMotTqASILThrshldExcdChks " E2E protection";
CM_ SG_ 72 AdSecMotTqASILThrshldExcdCntr " E2E protection";
CM_ SG_ 72 AdSecMotTqASILThrshldExcdThrshldExceeded " Boolean stating if the current operation is within the ASIL-D area of the steering system.";
CM_ SG_ 259 SecPoseMonSafeChks "Secondary Pose monitoring Checksum";
CM_ SG_ 259 SecPoseMonSafeCntr "Secondary Pose monitoring Counter";
CM_ SG_ 259 SecPoseMonSafeLatErr "Secondary Pose monitoring Lateral Error";
CM_ SG_ 259 SecPoseMonSafeLgtErr "Secondary Pose monitoring Longitudinal Error";
CM_ SG_ 259 SecPoseMonSafeSafeQf "Secondary Pose monitoring Quality factor for Longitudinal, Lateral and Yaw Error";
CM_ SG_ 259 SecPoseMonSafeYawErr "Secondary Pose monitoring Yaw Error";
CM_ SG_ 259 SecSteerMotTqSteerMotTq " Steering motor torque";
CM_ SG_ 259 SecSteerMotTqSteerMotTqQf " Quality factor for SteerMotTq";
CM_ SG_ 259 SecWhlLockStsChks "Secondary Wheel lock and degradation status Checksum";
CM_ SG_ 259 SecWhlLockStsCntr "Secondary Wheel lock and degradation status Counter";
CM_ SG_ 259 SecWhlLockStsDegradedSts "Secondary Wheel lock and degradation status Wheel Lock degraded status";
CM_ SG_ 259 SecWhlLockStsLockSts "Secondary Wheel lock and degradation status Wheel Lock Status";
CM_ SG_ 259 SSMBDegradedchks " CRC";
CM_ SG_ 259 SSMBDegradedcntr " counter";
CM_ SG_ 259 SSMBDegradedSSMBDegraded " Secondry Channel Degradation";
CM_ SG_ 21 BrkDegradedRdntChks " Checksum";
CM_ SG_ 21 BrkDegradedRdntCntr " Counter";
CM_ SG_ 21 BrkDegradedRdntSts " Brake degraded status";
CM_ SG_ 32 AdSecWhlAgEstimdGroupSafeChks "AD secondary wheel angle feedback E2E Checksum";
CM_ SG_ 32 AdSecWhlAgEstimdGroupSafeCntr "AD secondary wheel angle feedback E2E Counter";
CM_ SG_ 32 AdSecWhlAgEstimdGroupSafeQf1 "AD secondary wheel angle feedback Quality Factor of the rack position¨";
CM_ SG_ 32 AdSecWhlAgEstimdGroupSafeWhlAg "AD secondary wheel angle feedback Wheel angle estimate";
CM_ SG_ 32 AdSecWhlAgEstimdGroupSafeWhlAgRate "AD secondary wheel angle feedback Wheel angle rate estimate.";
CM_ SG_ 32 SecWhlRotToothCntrChks "Added with SCR 515, Vehicle State 519G

WhlRotToothCntrRec signal with Qf. E2E Checksum";
CM_ SG_ 32 SecWhlRotToothCntrCntr "Added with SCR 515, Vehicle State 519G

WhlRotToothCntrRec signal with Qf. E2E Counter";
CM_ SG_ 32 SecWhlRotToothCntrWhlRotToothCntrFrntLe "Added with SCR 515, Vehicle State 519G

WhlRotToothCntrRec signal with Qf. Wheel rotation impulse counter front left. For one complete wheel revolution the counter will increase by 96 (with 48 magnetic pole-pairs)";
CM_ SG_ 32 SecWhlRotToothCntrWhlRotToothCntrFrntLeQf "Added with SCR 515, Vehicle State 519G

WhlRotToothCntrRec signal with Qf. Quality factor for front left wheel";
CM_ SG_ 32 SecWhlRotToothCntrWhlRotToothCntrFrntRi "Added with SCR 515, Vehicle State 519G

WhlRotToothCntrRec signal with Qf. Wheel rotation impulse counter front right. For one complete wheel revolution the counter will increase by 96 (with 48 magnetic pole-pairs)";
CM_ SG_ 32 SecWhlRotToothCntrWhlRotToothCntrFrntRiQf "Added with SCR 515, Vehicle State 519G

WhlRotToothCntrRec signal with Qf. Quality factor for front right wheel";
CM_ SG_ 32 SecWhlRotToothCntrWhlRotToothCntrReLe "Added with SCR 515, Vehicle State 519G

WhlRotToothCntrRec signal with Qf. Wheel rotation impulse counter rear left. For one complete wheel revolution the counter will increase by 96 (with 48 magnetic pole-pairs)";
CM_ SG_ 32 SecWhlRotToothCntrWhlRotToothCntrReLeQf "Added with SCR 515, Vehicle State 519G

WhlRotToothCntrRec signal with Qf. Quality factor for rear left wheel";
CM_ SG_ 32 SecWhlRotToothCntrWhlRotToothCntrReRi "Added with SCR 515, Vehicle State 519G

WhlRotToothCntrRec signal with Qf. Wheel rotation impulse counter Rear right. For one complete wheel revolution the counter will increase by 96 (with 48 magnetic pole-pairs)";
CM_ SG_ 32 SecWhlRotToothCntrWhlRotToothCntrReRiQf "Added with SCR 515, Vehicle State 519G

WhlRotToothCntrRec signal with Qf. Quality factor for rear right wheel";
CM_ SG_ 49 SecALatDataRawSafeChks "Lateral acceleration estimation (Secondary) Checksum";
CM_ SG_ 49 SecALatDataRawSafeCntr "Lateral acceleration estimation (Secondary) Counter";
CM_ SG_ 49 SecALatDataRawSafeMax "Lateral acceleration estimation (Secondary) Maximum Lateral Acceleration";
CM_ SG_ 49 SecALatDataRawSafeMin "Lateral acceleration estimation (Secondary) Minimum Lateral Acceleration";
CM_ SG_ 49 SecALatDataRawSafeMinMaxQf "Lateral acceleration estimation (Secondary) Quality factor for Min and Max signals";
CM_ SG_ 49 SecALatDataRawSafeNom "Lateral acceleration estimation (Secondary) Nominal Lateral Acceleration";
CM_ SG_ 49 SecALatDataRawSafeNomQf "Lateral acceleration estimation (Secondary) Quality factor for Nom signal";
CM_ SG_ 49 SecALgtDataRawSafeChks "Longitudinal acceleration estimation (Secondary) Checksum";
CM_ SG_ 49 SecALgtDataRawSafeCntr "Longitudinal acceleration estimation (Secondary) Counter";
CM_ SG_ 49 SecALgtDataRawSafeMax "Longitudinal acceleration estimation (Secondary) Maximum longitudinal acceleration";
CM_ SG_ 49 SecALgtDataRawSafeMin "Longitudinal acceleration estimation (Secondary) Minimum longitudinal acceleration";
CM_ SG_ 49 SecALgtDataRawSafeMinMaxQf "Longitudinal acceleration estimation (Secondary) Quality factor for Min and Max signals";
CM_ SG_ 49 SecALgtDataRawSafeNom "Longitudinal acceleration estimation (Secondary) Nominal longitudinal acceleration";
CM_ SG_ 49 SecALgtDataRawSafeNomQf "Longitudinal acceleration estimation (Secondary) Quality factor for Nom signal";
CM_ SG_ 49 SecAxleSlipStsAndRelAgFrntAxle "Secondary:
---------
It contains Front and Rear Axle Slip status, Intervention Status and Relative Roll & Pitch informations. Front axle slip status";
CM_ SG_ 49 SecAxleSlipStsAndRelAgIntvSts "Secondary:
---------
It contains Front and Rear Axle Slip status, Intervention Status and Relative Roll & Pitch informations. Intervention status";
CM_ SG_ 49 SecAxleSlipStsAndRelAgReAxle "Secondary:
---------
It contains Front and Rear Axle Slip status, Intervention Status and Relative Roll & Pitch informations. Rear axle slip status";
CM_ SG_ 49 SecAxleSlipStsAndRelAgRelPitch "Secondary:
---------
It contains Front and Rear Axle Slip status, Intervention Status and Relative Roll & Pitch informations. Relative Pitch";
CM_ SG_ 49 SecAxleSlipStsAndRelAgRelPitchQf "Secondary:
---------
It contains Front and Rear Axle Slip status, Intervention Status and Relative Roll & Pitch informations. Qulality Factor of Relative Pitch";
CM_ SG_ 49 SecAxleSlipStsAndRelAgRelRoll "Secondary:
---------
It contains Front and Rear Axle Slip status, Intervention Status and Relative Roll & Pitch informations. Relative Roll";
CM_ SG_ 49 SecAxleSlipStsAndRelAgRelRolQf "Secondary:
---------
It contains Front and Rear Axle Slip status, Intervention Status and Relative Roll & Pitch informations. Qulality Factor of Relative Roll";
CM_ SG_ 49 SecVLatSafeChks "Lateral Velocity estimation (Secondary) Checksum";
CM_ SG_ 49 SecVLatSafeCntr "Lateral Velocity estimation (Secondary) Counter";
CM_ SG_ 49 SecVLatSafeMax "Lateral Velocity estimation (Secondary) Maximum Lateral Velocity";
CM_ SG_ 49 SecVLatSafeMin "Lateral Velocity estimation (Secondary) Minimum Lateral Velocity";
CM_ SG_ 49 SecVLatSafeMinMaxQf "Lateral Velocity estimation (Secondary) Quality factor for Min and Max signals";
CM_ SG_ 49 SecVLatSafeNom "Lateral Velocity estimation (Secondary) Nominal Lateral Velocity";
CM_ SG_ 49 SecVLatSafeNomQf "Lateral Velocity estimation (Secondary) Quality Factor for Nom signal";
CM_ SG_ 49 SecWhlRotDirReSafeChks "Wheel Rotation direction for Rear left and Rear right. E2E checksum";
CM_ SG_ 49 SecWhlRotDirReSafeCntr "Wheel Rotation direction for Rear left and Rear right. E2E Counter";
CM_ SG_ 49 SecWhlRotDirReSafeLe "Wheel Rotation direction for Rear left and Rear right. Left wheel";
CM_ SG_ 49 SecWhlRotDirReSafeLeQf "Wheel Rotation direction for Rear left and Rear right. Qualilty factor of left wheel rotation";
CM_ SG_ 49 SecWhlRotDirReSafeRi "Wheel Rotation direction for Rear left and Rear right. Right wheel";
CM_ SG_ 49 SecWhlRotDirReSafeRiQf "Wheel Rotation direction for Rear left and Rear right. Quality factor of right wheel rotation";
CM_ SG_ 49 SecYawRateSafeChks "Yaw Rate Estimation (Secondary) Checksum";
CM_ SG_ 49 SecYawRateSafeCntr "Yaw Rate Estimation (Secondary) Counter";
CM_ SG_ 49 SecYawRateSafeMax "Yaw Rate Estimation (Secondary) Maximum Yaw Rate";
CM_ SG_ 49 SecYawRateSafeMin "Yaw Rate Estimation (Secondary) Minimum Yaw Rate";
CM_ SG_ 49 SecYawRateSafeMinMaxQf "Yaw Rate Estimation (Secondary) Quality factor for Min and Max signals";
CM_ SG_ 49 SecYawRateSafeNom "Yaw Rate Estimation (Secondary) Nominal Yaw Rate";
CM_ SG_ 49 SecYawRateSafeNomQf "Yaw Rate Estimation (Secondary) Quality factor for Nom signal";
CM_ SG_ 122 SecVehSpdGroupSafeChks "Vehicle speed over ground and Moving direction (Secondary) Checksum";
CM_ SG_ 122 SecVehSpdGroupSafeCntr "Vehicle speed over ground and Moving direction (Secondary) Counter";
CM_ SG_ 122 SecVehSpdGroupSafeMax "Vehicle speed over ground and Moving direction (Secondary) Maximum vehicle speed over ground";
CM_ SG_ 122 SecVehSpdGroupSafeMin "Vehicle speed over ground and Moving direction (Secondary) Minimum vehicle speed over ground";
CM_ SG_ 122 SecVehSpdGroupSafeMinMaxQf "Vehicle speed over ground and Moving direction (Secondary) Quality factor for Min and Max signals";
CM_ SG_ 122 SecVehSpdGroupSafeMovDir "Vehicle speed over ground and Moving direction (Secondary) Actual moving direction";
CM_ SG_ 122 SecVehSpdGroupSafeMovDirQf "Vehicle speed over ground and Moving direction (Secondary) Quality factor for Actual moving direction";
CM_ SG_ 122 SecVehSpdGroupSafeNom "Vehicle speed over ground and Moving direction (Secondary) Nominal vehicle speed over ground";
CM_ SG_ 122 SecVehSpdGroupSafeNomQf "Vehicle speed over ground and Moving direction (Secondary) Quality factor for Nom signal";
CM_ SG_ 52 SecVehMSafeChks "Vehicle Mass estimation E2E Checksum";
CM_ SG_ 52 SecVehMSafeCntr "Vehicle Mass estimation E2E Conter";
CM_ SG_ 52 SecVehMSafeNomQf "Vehicle Mass estimation Vehicle Mass Nominal Quality factor ";
CM_ SG_ 52 SecVehMSafeSafeQf "Vehicle Mass estimation Vehicle Mass Min Max Quality factor ";
CM_ SG_ 52 SecVehMSafeVehMMax "Vehicle Mass estimation Vehicle Mass Maximum Value";
CM_ SG_ 52 SecVehMSafeVehMMin "Vehicle Mass estimation Vehicle Mass Minimum Value";
CM_ SG_ 52 SecVehMSafeVehMNom "Vehicle Mass estimation Vehicle Mass Nominal Value";
CM_ SG_ 52 SecWhlAgSpdFrntSafeChks "Wheel angle speed front wheels, secondary channel

Added with SCR 1972, Vehicle State 519G Checksum";
CM_ SG_ 52 SecWhlAgSpdFrntSafeCntr "Wheel angle speed front wheels, secondary channel

Added with SCR 1972, Vehicle State 519G Counter";
CM_ SG_ 52 SecWhlAgSpdFrntSafeLe "Wheel angle speed front wheels, secondary channel

Added with SCR 1972, Vehicle State 519G Angular velocity of left wheel.";
CM_ SG_ 52 SecWhlAgSpdFrntSafeLeQf "Wheel angle speed front wheels, secondary channel

Added with SCR 1972, Vehicle State 519G Qf for wheel speed sensor";
CM_ SG_ 52 SecWhlAgSpdFrntSafeRi "Wheel angle speed front wheels, secondary channel

Added with SCR 1972, Vehicle State 519G Angular velocity of right wheel.";
CM_ SG_ 52 SecWhlAgSpdFrntSafeRiQf "Wheel angle speed front wheels, secondary channel

Added with SCR 1972, Vehicle State 519G Qf for wheel speed sensor";
CM_ SG_ 52 SecWhlAgSpdReSafeChks "Wheel angle speed rear wheels, secondary channel

Added with SCR 1972, Vehicle State 519G Checksum";
CM_ SG_ 52 SecWhlAgSpdReSafeCntr "Wheel angle speed rear wheels, secondary channel

Added with SCR 1972, Vehicle State 519G Counter";
CM_ SG_ 52 SecWhlAgSpdReSafeLe "Wheel angle speed rear wheels, secondary channel

Added with SCR 1972, Vehicle State 519G Angular velocity of left wheel.";
CM_ SG_ 52 SecWhlAgSpdReSafeLeQf "Wheel angle speed rear wheels, secondary channel

Added with SCR 1972, Vehicle State 519G Qf for wheel speed sensor";
CM_ SG_ 52 SecWhlAgSpdReSafeRi "Wheel angle speed rear wheels, secondary channel

Added with SCR 1972, Vehicle State 519G Angular velocity of right wheel.";
CM_ SG_ 52 SecWhlAgSpdReSafeRiQf "Wheel angle speed rear wheels, secondary channel

Added with SCR 1972, Vehicle State 519G Qf for wheel speed sensor";
CM_ SG_ 85 AdSecSafeStopActvGroupSafeChks "Platform safe stop, secondary channel E2E checksum";
CM_ SG_ 85 AdSecSafeStopActvGroupSafeCntr "Platform safe stop, secondary channel E2E counter";
CM_ SG_ 85 AdSecSafeStopActvGroupSafePlatformSafeStopActv "Platform safe stop, secondary channel Safe stop active";
CM_ SG_ 85 AdSecWhlAgRateLimEstimdSafeAdWhlAgRate1 " Maximum wheel angle rate calculated from limited rack position rate";
CM_ SG_ 85 AdSecWhlAgRateLimEstimdSafeChks " Checksum";
CM_ SG_ 85 AdSecWhlAgRateLimEstimdSafeCntr " Counter";
CM_ SG_ 85 SecMaxALatEstimdGroupAcceleration " Maximum lateral acceleration";
CM_ SG_ 85 SecMaxALatEstimdGroupJerk " Maximum lateral acceleration rate";
CM_ SG_ 256 AdSecSafeStopReqSafeChks "Safe stop request E2E checksum";
CM_ SG_ 256 AdSecSafeStopReqSafeCntr "Safe stop request E2E counter";
CM_ SG_ 256 AdSecSafeStopReqSafeSafeStopReq "Safe stop request Safe stop request";
CM_ SG_ 256 SDSFltMgrStsRdntChks "SDS Fault Manager Status is to communicate the fault status to SSMB (ASIL D) CRC";
CM_ SG_ 256 SDSFltMgrStsRdntCntr "SDS Fault Manager Status is to communicate the fault status to SSMB (ASIL D) Counter";
CM_ SG_ 256 SDSFltMgrStsRdntSDSFltMgrStsRdnt "SDS Fault Manager Status is to communicate the fault status to SSMB (ASIL D)";
CM_ SG_ 65 AdSecPoseAX "POSE information Acceleration X";
CM_ SG_ 65 AdSecPoseAXConf "POSE information Confidence for acceleration X";
CM_ SG_ 65 AdSecPoseAY "POSE information Acceleration Y";
CM_ SG_ 65 AdSecPoseAYConf "POSE information Confidence for acceleration Y";
CM_ SG_ 65 AdSecPoseAZ "POSE information Acceleration Z";
CM_ SG_ 65 AdSecPoseAZConf "POSE information Confidence for acceleration Z";
CM_ SG_ 65 AdSecPoseChks "POSE information E2E profile 5 Check Sum";
CM_ SG_ 65 AdSecPoseCntr "POSE information E2E profile 5 counter";
CM_ SG_ 65 AdSecPoseDataID "POSE information E2E profile 5 Data ID";
CM_ SG_ 65 AdSecPosePitch "POSE information Pitch";
CM_ SG_ 65 AdSecPosePitchConf "POSE information Confidence for pitch";
CM_ SG_ 65 AdSecPosePitchRate "POSE information Pitch rate";
CM_ SG_ 65 AdSecPosePitchRateConf "POSE information Confidence for Pitch rate";
CM_ SG_ 65 AdSecPosePosX "POSE information Position X";
CM_ SG_ 65 AdSecPosePosXConf "POSE information Confidence for position X";
CM_ SG_ 65 AdSecPosePosY "POSE information Position Y";
CM_ SG_ 65 AdSecPosePosYConf "POSE information Confidence for position Y";
CM_ SG_ 65 AdSecPoseRoll "POSE information Roll";
CM_ SG_ 65 AdSecPoseRollConf "POSE information Confidence for Roll";
CM_ SG_ 65 AdSecPoseRollRate "POSE information Roll rate";
CM_ SG_ 65 AdSecPoseRollRateConf "POSE information Confidence for roll rate";
CM_ SG_ 65 AdSecPoseTiStampNanoSec "POSE information Time Stamp Nano Second";
CM_ SG_ 65 AdSecPoseTiStampSec "POSE information Time stampSecond";
CM_ SG_ 65 AdSecPoseVX "POSE information Velocity X";
CM_ SG_ 65 AdSecPoseVXConf "POSE information Confidence for velocity X";
CM_ SG_ 65 AdSecPoseVY "POSE information Velocity Y";
CM_ SG_ 65 AdSecPoseVYConf "POSE information Confidence for velocity Y";
CM_ SG_ 65 AdSecPoseYaw "POSE information Yaw";
CM_ SG_ 65 AdSecPoseYawConf "POSE information Confidence for yaw";
CM_ SG_ 65 AdSecPoseYawRate "POSE information Yaw rate";
CM_ SG_ 65 AdSecPoseYawRateConf "POSE information Confidence for yaw rate";
CM_ SG_ 144 SecRoadGradientlFromAdBanking "Estimated road gradients, secondary channels Road banking";
CM_ SG_ 144 SecRoadGradientlFromAdBankingConf "Estimated road gradients, secondary channels Banking confidence";
CM_ SG_ 144 SecRoadGradientlFromAdChks "Estimated road gradients, secondary channels E2E checksum";
CM_ SG_ 144 SecRoadGradientlFromAdCntr "Estimated road gradients, secondary channels E2E counter";
CM_ SG_ 144 SecRoadGradientlFromAdIncln "Estimated road gradients, secondary channels Road inclination";
CM_ SG_ 144 SecRoadGradientlFromAdInclnConf "Estimated road gradients, secondary channels Inclination confidence";
CM_ SG_ 38 AdSecWhlAgReqGroupSafeChks "AD Requested wheel angle, secondary channel E2E Checksum";
CM_ SG_ 38 AdSecWhlAgReqGroupSafeCntr "AD Requested wheel angle, secondary channel E2E Counter";
CM_ SG_ 38 AdSecWhlAgReqGroupSafeWhlAgReq "AD Requested wheel angle, secondary channel The requested wheel angle. The wheel angle is supervised by the LatCtrl ASIL D supervisory controller before being converted to an ASIL D rack position request.";
CM_ SG_ 272 AdSecPSSGroupSafe0Chks "Platform Safe Stop buffer paths. 

All signalgroups cover 50 points + 1 initial point. Each point has delta X, Y, time and heading. All signal groups are tied together with a trajectory id. 
All signalgroups include signals for E2E protection using profile 5 according to Autosar 4.2.2.

Signal group 0 includes:
* Initial point
* PSS point 1 and 2 E2E checksum, profile 5";
CM_ SG_ 272 AdSecPSSGroupSafe0Cntr "Platform Safe Stop buffer paths. 

All signalgroups cover 50 points + 1 initial point. Each point has delta X, Y, time and heading. All signal groups are tied together with a trajectory id. 
All signalgroups include signals for E2E protection using profile 5 according to Autosar 4.2.2.

Signal group 0 includes:
* Initial point
* PSS point 1 and 2 E2E Counter, profile 5";
CM_ SG_ 272 AdSecPSSGroupSafe0DataID "Platform Safe Stop buffer paths. 

All signalgroups cover 50 points + 1 initial point. Each point has delta X, Y, time and heading. All signal groups are tied together with a trajectory id. 
All signalgroups include signals for E2E protection using profile 5 according to Autosar 4.2.2.

Signal group 0 includes:
* Initial point
* PSS point 1 and 2 E2E Data ID, profile 5";
CM_ SG_ 272 AdSecPSSGroupSafe0DeltaTPos1 "Platform Safe Stop buffer paths. 

All signalgroups cover 50 points + 1 initial point. Each point has delta X, Y, time and heading. All signal groups are tied together with a trajectory id. 
All signalgroups include signals for E2E protection using profile 5 according to Autosar 4.2.2.

Signal group 0 includes:
* Initial point
* PSS point 1 and 2 Delta time position 1";
CM_ SG_ 272 AdSecPSSGroupSafe0DeltaTPos2 "Platform Safe Stop buffer paths. 

All signalgroups cover 50 points + 1 initial point. Each point has delta X, Y, time and heading. All signal groups are tied together with a trajectory id. 
All signalgroups include signals for E2E protection using profile 5 according to Autosar 4.2.2.

Signal group 0 includes:
* Initial point
* PSS point 1 and 2 Delta time position 2";
CM_ SG_ 272 AdSecPSSGroupSafe0DeltaXPos1 "Platform Safe Stop buffer paths. 

All signalgroups cover 50 points + 1 initial point. Each point has delta X, Y, time and heading. All signal groups are tied together with a trajectory id. 
All signalgroups include signals for E2E protection using profile 5 according to Autosar 4.2.2.

Signal group 0 includes:
* Initial point
* PSS point 1 and 2 Delta X position 1";
CM_ SG_ 272 AdSecPSSGroupSafe0DeltaXPos2 "Platform Safe Stop buffer paths. 

All signalgroups cover 50 points + 1 initial point. Each point has delta X, Y, time and heading. All signal groups are tied together with a trajectory id. 
All signalgroups include signals for E2E protection using profile 5 according to Autosar 4.2.2.

Signal group 0 includes:
* Initial point
* PSS point 1 and 2 Delta X position 2";
CM_ SG_ 272 AdSecPSSGroupSafe0DeltaYPos1 "Platform Safe Stop buffer paths. 

All signalgroups cover 50 points + 1 initial point. Each point has delta X, Y, time and heading. All signal groups are tied together with a trajectory id. 
All signalgroups include signals for E2E protection using profile 5 according to Autosar 4.2.2.

Signal group 0 includes:
* Initial point
* PSS point 1 and 2 Delta Y position 1";
CM_ SG_ 272 AdSecPSSGroupSafe0DeltaYPos2 "Platform Safe Stop buffer paths. 

All signalgroups cover 50 points + 1 initial point. Each point has delta X, Y, time and heading. All signal groups are tied together with a trajectory id. 
All signalgroups include signals for E2E protection using profile 5 according to Autosar 4.2.2.

Signal group 0 includes:
* Initial point
* PSS point 1 and 2 Delta Y position 2";
CM_ SG_ 272 AdSecPSSGroupSafe0HeadingPos1 "Platform Safe Stop buffer paths. 

All signalgroups cover 50 points + 1 initial point. Each point has delta X, Y, time and heading. All signal groups are tied together with a trajectory id. 
All signalgroups include signals for E2E protection using profile 5 according to Autosar 4.2.2.

Signal group 0 includes:
* Initial point
* PSS point 1 and 2 Heading position 1";
CM_ SG_ 272 AdSecPSSGroupSafe0HeadingPos2 "Platform Safe Stop buffer paths. 

All signalgroups cover 50 points + 1 initial point. Each point has delta X, Y, time and heading. All signal groups are tied together with a trajectory id. 
All signalgroups include signals for E2E protection using profile 5 according to Autosar 4.2.2.

Signal group 0 includes:
* Initial point
* PSS point 1 and 2 Heading position 2";
CM_ SG_ 272 AdSecPSSGroupSafe0InitHeading "Platform Safe Stop buffer paths. 

All signalgroups cover 50 points + 1 initial point. Each point has delta X, Y, time and heading. All signal groups are tied together with a trajectory id. 
All signalgroups include signals for E2E protection using profile 5 according to Autosar 4.2.2.

Signal group 0 includes:
* Initial point
* PSS point 1 and 2 Init heading";
CM_ SG_ 272 AdSecPSSGroupSafe0InitPosX "Platform Safe Stop buffer paths. 

All signalgroups cover 50 points + 1 initial point. Each point has delta X, Y, time and heading. All signal groups are tied together with a trajectory id. 
All signalgroups include signals for E2E protection using profile 5 according to Autosar 4.2.2.

Signal group 0 includes:
* Initial point
* PSS point 1 and 2 Init position X";
CM_ SG_ 272 AdSecPSSGroupSafe0InitPosY "Platform Safe Stop buffer paths. 

All signalgroups cover 50 points + 1 initial point. Each point has delta X, Y, time and heading. All signal groups are tied together with a trajectory id. 
All signalgroups include signals for E2E protection using profile 5 according to Autosar 4.2.2.

Signal group 0 includes:
* Initial point
* PSS point 1 and 2 Init position Y";
CM_ SG_ 272 AdSecPSSGroupSafe0TiStampNanoSec "Platform Safe Stop buffer paths. 

All signalgroups cover 50 points + 1 initial point. Each point has delta X, Y, time and heading. All signal groups are tied together with a trajectory id. 
All signalgroups include signals for E2E protection using profile 5 according to Autosar 4.2.2.

Signal group 0 includes:
* Initial point
* PSS point 1 and 2 Time stamp, nano seconds";
CM_ SG_ 272 AdSecPSSGroupSafe0TiStampSec "Platform Safe Stop buffer paths. 

All signalgroups cover 50 points + 1 initial point. Each point has delta X, Y, time and heading. All signal groups are tied together with a trajectory id. 
All signalgroups include signals for E2E protection using profile 5 according to Autosar 4.2.2.

Signal group 0 includes:
* Initial point
* PSS point 1 and 2 Time stamp, seconds";
CM_ SG_ 272 AdSecPSSGroupSafe0TrajectID "Platform Safe Stop buffer paths. 

All signalgroups cover 50 points + 1 initial point. Each point has delta X, Y, time and heading. All signal groups are tied together with a trajectory id. 
All signalgroups include signals for E2E protection using profile 5 according to Autosar 4.2.2.

Signal group 0 includes:
* Initial point
* PSS point 1 and 2 Trajectory ID";
CM_ SG_ 278 AdSecPSSGroupSafe1Chks "Platform Safe Stop buffer paths. 

All signalgroups cover 50 points + 1 initial point. Each point has delta X, Y, time and heading. All signal groups are tied together with a trajectory id. 
All signalgroups include signals for E2E protection using profile 5 according to Autosar 4.2.2.

Signal group 1 includes:
* 6 PSS points, with overall sequence 3-8
 E2E checksum, profile 5";
CM_ SG_ 278 AdSecPSSGroupSafe1Cntr "Platform Safe Stop buffer paths. 

All signalgroups cover 50 points + 1 initial point. Each point has delta X, Y, time and heading. All signal groups are tied together with a trajectory id. 
All signalgroups include signals for E2E protection using profile 5 according to Autosar 4.2.2.

Signal group 1 includes:
* 6 PSS points, with overall sequence 3-8
 E2E counter, profile 5";
CM_ SG_ 278 AdSecPSSGroupSafe1DataID "Platform Safe Stop buffer paths. 

All signalgroups cover 50 points + 1 initial point. Each point has delta X, Y, time and heading. All signal groups are tied together with a trajectory id. 
All signalgroups include signals for E2E protection using profile 5 according to Autosar 4.2.2.

Signal group 1 includes:
* 6 PSS points, with overall sequence 3-8
 E2E Data ID, profile 5";
CM_ SG_ 278 AdSecPSSGroupSafe1DeltaTPos1 "Platform Safe Stop buffer paths. 

All signalgroups cover 50 points + 1 initial point. Each point has delta X, Y, time and heading. All signal groups are tied together with a trajectory id. 
All signalgroups include signals for E2E protection using profile 5 according to Autosar 4.2.2.

Signal group 1 includes:
* 6 PSS points, with overall sequence 3-8
 Delta time position 1";
CM_ SG_ 278 AdSecPSSGroupSafe1DeltaTPos2 "Platform Safe Stop buffer paths. 

All signalgroups cover 50 points + 1 initial point. Each point has delta X, Y, time and heading. All signal groups are tied together with a trajectory id. 
All signalgroups include signals for E2E protection using profile 5 according to Autosar 4.2.2.

Signal group 1 includes:
* 6 PSS points, with overall sequence 3-8
 Delta time position 2";
CM_ SG_ 278 AdSecPSSGroupSafe1DeltaTPos3 "Platform Safe Stop buffer paths. 

All signalgroups cover 50 points + 1 initial point. Each point has delta X, Y, time and heading. All signal groups are tied together with a trajectory id. 
All signalgroups include signals for E2E protection using profile 5 according to Autosar 4.2.2.

Signal group 1 includes:
* 6 PSS points, with overall sequence 3-8
 Delta time position 3";
CM_ SG_ 278 AdSecPSSGroupSafe1DeltaTPos4 "Platform Safe Stop buffer paths. 

All signalgroups cover 50 points + 1 initial point. Each point has delta X, Y, time and heading. All signal groups are tied together with a trajectory id. 
All signalgroups include signals for E2E protection using profile 5 according to Autosar 4.2.2.

Signal group 1 includes:
* 6 PSS points, with overall sequence 3-8
 Delta time position 4";
CM_ SG_ 278 AdSecPSSGroupSafe1DeltaTPos5 "Platform Safe Stop buffer paths. 

All signalgroups cover 50 points + 1 initial point. Each point has delta X, Y, time and heading. All signal groups are tied together with a trajectory id. 
All signalgroups include signals for E2E protection using profile 5 according to Autosar 4.2.2.

Signal group 1 includes:
* 6 PSS points, with overall sequence 3-8
 Delta time position 5";
CM_ SG_ 278 AdSecPSSGroupSafe1DeltaTPos6 "Platform Safe Stop buffer paths. 

All signalgroups cover 50 points + 1 initial point. Each point has delta X, Y, time and heading. All signal groups are tied together with a trajectory id. 
All signalgroups include signals for E2E protection using profile 5 according to Autosar 4.2.2.

Signal group 1 includes:
* 6 PSS points, with overall sequence 3-8
 Delta time position 6";
CM_ SG_ 278 AdSecPSSGroupSafe1DeltaXPos1 "Platform Safe Stop buffer paths. 

All signalgroups cover 50 points + 1 initial point. Each point has delta X, Y, time and heading. All signal groups are tied together with a trajectory id. 
All signalgroups include signals for E2E protection using profile 5 according to Autosar 4.2.2.

Signal group 1 includes:
* 6 PSS points, with overall sequence 3-8
 Delta X position 1";
CM_ SG_ 278 AdSecPSSGroupSafe1DeltaXPos2 "Platform Safe Stop buffer paths. 

All signalgroups cover 50 points + 1 initial point. Each point has delta X, Y, time and heading. All signal groups are tied together with a trajectory id. 
All signalgroups include signals for E2E protection using profile 5 according to Autosar 4.2.2.

Signal group 1 includes:
* 6 PSS points, with overall sequence 3-8
 Delta X position 2";
CM_ SG_ 278 AdSecPSSGroupSafe1DeltaXPos3 "Platform Safe Stop buffer paths. 

All signalgroups cover 50 points + 1 initial point. Each point has delta X, Y, time and heading. All signal groups are tied together with a trajectory id. 
All signalgroups include signals for E2E protection using profile 5 according to Autosar 4.2.2.

Signal group 1 includes:
* 6 PSS points, with overall sequence 3-8
 Delta X position 3";
CM_ SG_ 278 AdSecPSSGroupSafe1DeltaXPos4 "Platform Safe Stop buffer paths. 

All signalgroups cover 50 points + 1 initial point. Each point has delta X, Y, time and heading. All signal groups are tied together with a trajectory id. 
All signalgroups include signals for E2E protection using profile 5 according to Autosar 4.2.2.

Signal group 1 includes:
* 6 PSS points, with overall sequence 3-8
 Delta X position 4";
CM_ SG_ 278 AdSecPSSGroupSafe1DeltaXPos5 "Platform Safe Stop buffer paths. 

All signalgroups cover 50 points + 1 initial point. Each point has delta X, Y, time and heading. All signal groups are tied together with a trajectory id. 
All signalgroups include signals for E2E protection using profile 5 according to Autosar 4.2.2.

Signal group 1 includes:
* 6 PSS points, with overall sequence 3-8
 Delta X position 5";
CM_ SG_ 278 AdSecPSSGroupSafe1DeltaXPos6 "Platform Safe Stop buffer paths. 

All signalgroups cover 50 points + 1 initial point. Each point has delta X, Y, time and heading. All signal groups are tied together with a trajectory id. 
All signalgroups include signals for E2E protection using profile 5 according to Autosar 4.2.2.

Signal group 1 includes:
* 6 PSS points, with overall sequence 3-8
 Delta X position 6";
CM_ SG_ 278 AdSecPSSGroupSafe1DeltaYPos1 "Platform Safe Stop buffer paths. 

All signalgroups cover 50 points + 1 initial point. Each point has delta X, Y, time and heading. All signal groups are tied together with a trajectory id. 
All signalgroups include signals for E2E protection using profile 5 according to Autosar 4.2.2.

Signal group 1 includes:
* 6 PSS points, with overall sequence 3-8
 Delta Y position 1";
CM_ SG_ 278 AdSecPSSGroupSafe1DeltaYPos2 "Platform Safe Stop buffer paths. 

All signalgroups cover 50 points + 1 initial point. Each point has delta X, Y, time and heading. All signal groups are tied together with a trajectory id. 
All signalgroups include signals for E2E protection using profile 5 according to Autosar 4.2.2.

Signal group 1 includes:
* 6 PSS points, with overall sequence 3-8
 Delta Y position 2";
CM_ SG_ 278 AdSecPSSGroupSafe1DeltaYPos3 "Platform Safe Stop buffer paths. 

All signalgroups cover 50 points + 1 initial point. Each point has delta X, Y, time and heading. All signal groups are tied together with a trajectory id. 
All signalgroups include signals for E2E protection using profile 5 according to Autosar 4.2.2.

Signal group 1 includes:
* 6 PSS points, with overall sequence 3-8
 Delta Y position 3";
CM_ SG_ 278 AdSecPSSGroupSafe1DeltaYPos4 "Platform Safe Stop buffer paths. 

All signalgroups cover 50 points + 1 initial point. Each point has delta X, Y, time and heading. All signal groups are tied together with a trajectory id. 
All signalgroups include signals for E2E protection using profile 5 according to Autosar 4.2.2.

Signal group 1 includes:
* 6 PSS points, with overall sequence 3-8
 Delta Y position 4";
CM_ SG_ 278 AdSecPSSGroupSafe1DeltaYPos5 "Platform Safe Stop buffer paths. 

All signalgroups cover 50 points + 1 initial point. Each point has delta X, Y, time and heading. All signal groups are tied together with a trajectory id. 
All signalgroups include signals for E2E protection using profile 5 according to Autosar 4.2.2.

Signal group 1 includes:
* 6 PSS points, with overall sequence 3-8
 Delta Y position 5";
CM_ SG_ 278 AdSecPSSGroupSafe1DeltaYPos6 "Platform Safe Stop buffer paths. 

All signalgroups cover 50 points + 1 initial point. Each point has delta X, Y, time and heading. All signal groups are tied together with a trajectory id. 
All signalgroups include signals for E2E protection using profile 5 according to Autosar 4.2.2.

Signal group 1 includes:
* 6 PSS points, with overall sequence 3-8
 Delta Y position 6";
CM_ SG_ 278 AdSecPSSGroupSafe1HeadingPos1 "Platform Safe Stop buffer paths. 

All signalgroups cover 50 points + 1 initial point. Each point has delta X, Y, time and heading. All signal groups are tied together with a trajectory id. 
All signalgroups include signals for E2E protection using profile 5 according to Autosar 4.2.2.

Signal group 1 includes:
* 6 PSS points, with overall sequence 3-8
 Heading position 1";
CM_ SG_ 278 AdSecPSSGroupSafe1HeadingPos2 "Platform Safe Stop buffer paths. 

All signalgroups cover 50 points + 1 initial point. Each point has delta X, Y, time and heading. All signal groups are tied together with a trajectory id. 
All signalgroups include signals for E2E protection using profile 5 according to Autosar 4.2.2.

Signal group 1 includes:
* 6 PSS points, with overall sequence 3-8
 Heading position 2";
CM_ SG_ 278 AdSecPSSGroupSafe1HeadingPos3 "Platform Safe Stop buffer paths. 

All signalgroups cover 50 points + 1 initial point. Each point has delta X, Y, time and heading. All signal groups are tied together with a trajectory id. 
All signalgroups include signals for E2E protection using profile 5 according to Autosar 4.2.2.

Signal group 1 includes:
* 6 PSS points, with overall sequence 3-8
 Heading position 3";
CM_ SG_ 278 AdSecPSSGroupSafe1HeadingPos4 "Platform Safe Stop buffer paths. 

All signalgroups cover 50 points + 1 initial point. Each point has delta X, Y, time and heading. All signal groups are tied together with a trajectory id. 
All signalgroups include signals for E2E protection using profile 5 according to Autosar 4.2.2.

Signal group 1 includes:
* 6 PSS points, with overall sequence 3-8
 Heading position 4";
CM_ SG_ 278 AdSecPSSGroupSafe1HeadingPos5 "Platform Safe Stop buffer paths. 

All signalgroups cover 50 points + 1 initial point. Each point has delta X, Y, time and heading. All signal groups are tied together with a trajectory id. 
All signalgroups include signals for E2E protection using profile 5 according to Autosar 4.2.2.

Signal group 1 includes:
* 6 PSS points, with overall sequence 3-8
 Heading position 5";
CM_ SG_ 278 AdSecPSSGroupSafe1HeadingPos6 "Platform Safe Stop buffer paths. 

All signalgroups cover 50 points + 1 initial point. Each point has delta X, Y, time and heading. All signal groups are tied together with a trajectory id. 
All signalgroups include signals for E2E protection using profile 5 according to Autosar 4.2.2.

Signal group 1 includes:
* 6 PSS points, with overall sequence 3-8
 Heading position 6";
CM_ SG_ 278 AdSecPSSGroupSafe1TrajectID "Platform Safe Stop buffer paths. 

All signalgroups cover 50 points + 1 initial point. Each point has delta X, Y, time and heading. All signal groups are tied together with a trajectory id. 
All signalgroups include signals for E2E protection using profile 5 according to Autosar 4.2.2.

Signal group 1 includes:
* 6 PSS points, with overall sequence 3-8
 Trajectory ID";
CM_ SG_ 281 AdSecPSSGroupSafe2Chks "Platform Safe Stop buffer paths. 

All signalgroups cover 50 points + 1 initial point. Each point has delta X, Y, time and heading. All signal groups are tied together with a trajectory id. 
All signalgroups include signals for E2E protection using profile 5 according to Autosar 4.2.2.

Signal group 2 includes:
* 6 PSS points, with overall sequence 9-14
 E2E checksum, profile 5";
CM_ SG_ 281 AdSecPSSGroupSafe2Cntr "Platform Safe Stop buffer paths. 

All signalgroups cover 50 points + 1 initial point. Each point has delta X, Y, time and heading. All signal groups are tied together with a trajectory id. 
All signalgroups include signals for E2E protection using profile 5 according to Autosar 4.2.2.

Signal group 2 includes:
* 6 PSS points, with overall sequence 9-14
 E2E counter, profile 5";
CM_ SG_ 281 AdSecPSSGroupSafe2DataID "Platform Safe Stop buffer paths. 

All signalgroups cover 50 points + 1 initial point. Each point has delta X, Y, time and heading. All signal groups are tied together with a trajectory id. 
All signalgroups include signals for E2E protection using profile 5 according to Autosar 4.2.2.

Signal group 2 includes:
* 6 PSS points, with overall sequence 9-14
 E2E Data ID, profile 5";
CM_ SG_ 281 AdSecPSSGroupSafe2DeltaTPos1 "Platform Safe Stop buffer paths. 

All signalgroups cover 50 points + 1 initial point. Each point has delta X, Y, time and heading. All signal groups are tied together with a trajectory id. 
All signalgroups include signals for E2E protection using profile 5 according to Autosar 4.2.2.

Signal group 2 includes:
* 6 PSS points, with overall sequence 9-14
 Delta time position 1";
CM_ SG_ 281 AdSecPSSGroupSafe2DeltaTPos2 "Platform Safe Stop buffer paths. 

All signalgroups cover 50 points + 1 initial point. Each point has delta X, Y, time and heading. All signal groups are tied together with a trajectory id. 
All signalgroups include signals for E2E protection using profile 5 according to Autosar 4.2.2.

Signal group 2 includes:
* 6 PSS points, with overall sequence 9-14
 Delta time position 2";
CM_ SG_ 281 AdSecPSSGroupSafe2DeltaTPos3 "Platform Safe Stop buffer paths. 

All signalgroups cover 50 points + 1 initial point. Each point has delta X, Y, time and heading. All signal groups are tied together with a trajectory id. 
All signalgroups include signals for E2E protection using profile 5 according to Autosar 4.2.2.

Signal group 2 includes:
* 6 PSS points, with overall sequence 9-14
 Delta time position 3";
CM_ SG_ 281 AdSecPSSGroupSafe2DeltaTPos4 "Platform Safe Stop buffer paths. 

All signalgroups cover 50 points + 1 initial point. Each point has delta X, Y, time and heading. All signal groups are tied together with a trajectory id. 
All signalgroups include signals for E2E protection using profile 5 according to Autosar 4.2.2.

Signal group 2 includes:
* 6 PSS points, with overall sequence 9-14
 Delta time position 4";
CM_ SG_ 281 AdSecPSSGroupSafe2DeltaTPos5 "Platform Safe Stop buffer paths. 

All signalgroups cover 50 points + 1 initial point. Each point has delta X, Y, time and heading. All signal groups are tied together with a trajectory id. 
All signalgroups include signals for E2E protection using profile 5 according to Autosar 4.2.2.

Signal group 2 includes:
* 6 PSS points, with overall sequence 9-14
 Delta time position 5";
CM_ SG_ 281 AdSecPSSGroupSafe2DeltaTPos6 "Platform Safe Stop buffer paths. 

All signalgroups cover 50 points + 1 initial point. Each point has delta X, Y, time and heading. All signal groups are tied together with a trajectory id. 
All signalgroups include signals for E2E protection using profile 5 according to Autosar 4.2.2.

Signal group 2 includes:
* 6 PSS points, with overall sequence 9-14
 Delta time position 6";
CM_ SG_ 281 AdSecPSSGroupSafe2DeltaXPos1 "Platform Safe Stop buffer paths. 

All signalgroups cover 50 points + 1 initial point. Each point has delta X, Y, time and heading. All signal groups are tied together with a trajectory id. 
All signalgroups include signals for E2E protection using profile 5 according to Autosar 4.2.2.

Signal group 2 includes:
* 6 PSS points, with overall sequence 9-14
 Delta X position 1";
CM_ SG_ 281 AdSecPSSGroupSafe2DeltaXPos2 "Platform Safe Stop buffer paths. 

All signalgroups cover 50 points + 1 initial point. Each point has delta X, Y, time and heading. All signal groups are tied together with a trajectory id. 
All signalgroups include signals for E2E protection using profile 5 according to Autosar 4.2.2.

Signal group 2 includes:
* 6 PSS points, with overall sequence 9-14
 Delta X position 2";
CM_ SG_ 281 AdSecPSSGroupSafe2DeltaXPos3 "Platform Safe Stop buffer paths. 

All signalgroups cover 50 points + 1 initial point. Each point has delta X, Y, time and heading. All signal groups are tied together with a trajectory id. 
All signalgroups include signals for E2E protection using profile 5 according to Autosar 4.2.2.

Signal group 2 includes:
* 6 PSS points, with overall sequence 9-14
 Delta X position 3";
CM_ SG_ 281 AdSecPSSGroupSafe2DeltaXPos4 "Platform Safe Stop buffer paths. 

All signalgroups cover 50 points + 1 initial point. Each point has delta X, Y, time and heading. All signal groups are tied together with a trajectory id. 
All signalgroups include signals for E2E protection using profile 5 according to Autosar 4.2.2.

Signal group 2 includes:
* 6 PSS points, with overall sequence 9-14
 Delta X position 4";
CM_ SG_ 281 AdSecPSSGroupSafe2DeltaXPos5 "Platform Safe Stop buffer paths. 

All signalgroups cover 50 points + 1 initial point. Each point has delta X, Y, time and heading. All signal groups are tied together with a trajectory id. 
All signalgroups include signals for E2E protection using profile 5 according to Autosar 4.2.2.

Signal group 2 includes:
* 6 PSS points, with overall sequence 9-14
 Delta X position 5";
CM_ SG_ 281 AdSecPSSGroupSafe2DeltaXPos6 "Platform Safe Stop buffer paths. 

All signalgroups cover 50 points + 1 initial point. Each point has delta X, Y, time and heading. All signal groups are tied together with a trajectory id. 
All signalgroups include signals for E2E protection using profile 5 according to Autosar 4.2.2.

Signal group 2 includes:
* 6 PSS points, with overall sequence 9-14
 Delta X position 6";
CM_ SG_ 281 AdSecPSSGroupSafe2DeltaYPos1 "Platform Safe Stop buffer paths. 

All signalgroups cover 50 points + 1 initial point. Each point has delta X, Y, time and heading. All signal groups are tied together with a trajectory id. 
All signalgroups include signals for E2E protection using profile 5 according to Autosar 4.2.2.

Signal group 2 includes:
* 6 PSS points, with overall sequence 9-14
 Delta Y position 1";
CM_ SG_ 281 AdSecPSSGroupSafe2DeltaYPos2 "Platform Safe Stop buffer paths. 

All signalgroups cover 50 points + 1 initial point. Each point has delta X, Y, time and heading. All signal groups are tied together with a trajectory id. 
All signalgroups include signals for E2E protection using profile 5 according to Autosar 4.2.2.

Signal group 2 includes:
* 6 PSS points, with overall sequence 9-14
 Delta Y position 2";
CM_ SG_ 281 AdSecPSSGroupSafe2DeltaYPos3 "Platform Safe Stop buffer paths. 

All signalgroups cover 50 points + 1 initial point. Each point has delta X, Y, time and heading. All signal groups are tied together with a trajectory id. 
All signalgroups include signals for E2E protection using profile 5 according to Autosar 4.2.2.

Signal group 2 includes:
* 6 PSS points, with overall sequence 9-14
 Delta Y position 3";
CM_ SG_ 281 AdSecPSSGroupSafe2DeltaYPos4 "Platform Safe Stop buffer paths. 

All signalgroups cover 50 points + 1 initial point. Each point has delta X, Y, time and heading. All signal groups are tied together with a trajectory id. 
All signalgroups include signals for E2E protection using profile 5 according to Autosar 4.2.2.

Signal group 2 includes:
* 6 PSS points, with overall sequence 9-14
 Delta Y position 4";
CM_ SG_ 281 AdSecPSSGroupSafe2DeltaYPos5 "Platform Safe Stop buffer paths. 

All signalgroups cover 50 points + 1 initial point. Each point has delta X, Y, time and heading. All signal groups are tied together with a trajectory id. 
All signalgroups include signals for E2E protection using profile 5 according to Autosar 4.2.2.

Signal group 2 includes:
* 6 PSS points, with overall sequence 9-14
 Delta Y position 5";
CM_ SG_ 281 AdSecPSSGroupSafe2DeltaYPos6 "Platform Safe Stop buffer paths. 

All signalgroups cover 50 points + 1 initial point. Each point has delta X, Y, time and heading. All signal groups are tied together with a trajectory id. 
All signalgroups include signals for E2E protection using profile 5 according to Autosar 4.2.2.

Signal group 2 includes:
* 6 PSS points, with overall sequence 9-14
 Delta Y position 6";
CM_ SG_ 281 AdSecPSSGroupSafe2HeadingPos1 "Platform Safe Stop buffer paths. 

All signalgroups cover 50 points + 1 initial point. Each point has delta X, Y, time and heading. All signal groups are tied together with a trajectory id. 
All signalgroups include signals for E2E protection using profile 5 according to Autosar 4.2.2.

Signal group 2 includes:
* 6 PSS points, with overall sequence 9-14
 Heading position 1";
CM_ SG_ 281 AdSecPSSGroupSafe2HeadingPos2 "Platform Safe Stop buffer paths. 

All signalgroups cover 50 points + 1 initial point. Each point has delta X, Y, time and heading. All signal groups are tied together with a trajectory id. 
All signalgroups include signals for E2E protection using profile 5 according to Autosar 4.2.2.

Signal group 2 includes:
* 6 PSS points, with overall sequence 9-14
 Heading position 2";
CM_ SG_ 281 AdSecPSSGroupSafe2HeadingPos3 "Platform Safe Stop buffer paths. 

All signalgroups cover 50 points + 1 initial point. Each point has delta X, Y, time and heading. All signal groups are tied together with a trajectory id. 
All signalgroups include signals for E2E protection using profile 5 according to Autosar 4.2.2.

Signal group 2 includes:
* 6 PSS points, with overall sequence 9-14
 Heading position 3";
CM_ SG_ 281 AdSecPSSGroupSafe2HeadingPos4 "Platform Safe Stop buffer paths. 

All signalgroups cover 50 points + 1 initial point. Each point has delta X, Y, time and heading. All signal groups are tied together with a trajectory id. 
All signalgroups include signals for E2E protection using profile 5 according to Autosar 4.2.2.

Signal group 2 includes:
* 6 PSS points, with overall sequence 9-14
 Heading position 4";
CM_ SG_ 281 AdSecPSSGroupSafe2HeadingPos5 "Platform Safe Stop buffer paths. 

All signalgroups cover 50 points + 1 initial point. Each point has delta X, Y, time and heading. All signal groups are tied together with a trajectory id. 
All signalgroups include signals for E2E protection using profile 5 according to Autosar 4.2.2.

Signal group 2 includes:
* 6 PSS points, with overall sequence 9-14
 Heading position 5";
CM_ SG_ 281 AdSecPSSGroupSafe2HeadingPos6 "Platform Safe Stop buffer paths. 

All signalgroups cover 50 points + 1 initial point. Each point has delta X, Y, time and heading. All signal groups are tied together with a trajectory id. 
All signalgroups include signals for E2E protection using profile 5 according to Autosar 4.2.2.

Signal group 2 includes:
* 6 PSS points, with overall sequence 9-14
 Heading position 6";
CM_ SG_ 281 AdSecPSSGroupSafe2TrajectID "Platform Safe Stop buffer paths. 

All signalgroups cover 50 points + 1 initial point. Each point has delta X, Y, time and heading. All signal groups are tied together with a trajectory id. 
All signalgroups include signals for E2E protection using profile 5 according to Autosar 4.2.2.

Signal group 2 includes:
* 6 PSS points, with overall sequence 9-14
 Trajectory ID";

// Attribute definitions
BA_DEF_  "BaudRateCANFD" FLOAT 1000 10000000; // [bps]
BA_DEF_  "Baudrate" INT 1000 1000000; // [bps]
BA_DEF_  "BusType" STRING;
BA_DEF_  "DBName" STRING;
BA_DEF_  "ProtocolType" STRING;
BA_DEF_ BU_ "NmAsrNode" ENUM "No","Yes";
BA_DEF_ BU_ "NmAsrNodeIdentifier" INT 0 255;
BA_DEF_ BO_ "CANFD_BRS" ENUM "0","1";
BA_DEF_ BO_ "GenMsgCycleTime" INT 0 65536; // [ms]
BA_DEF_ BO_ "GenMsgDelayTime" INT 0 65536; // [ms]
BA_DEF_ BO_ "GenMsgSendType" ENUM "cyclic", "spontaneous", "not-used", "not-used", "not-used", "cyclicAndSpontaneous", "not-used", "cyclicIfActive", "NoMsgSendType"; // [us]
BA_DEF_ BO_ "GenMsgStartDelayTime" INT 0 65536; // [ms]
BA_DEF_ BO_ "VFrameFormat" ENUM "StandardCAN","ExtendedCAN","reserved","J1939PG","reserved","reserved","reserved","reserved","reserved","reserved","reserved","reserved","reserved","reserved","StandardCAN_FD","ExtendedCAN_FD";
BA_DEF_ SG_ "GenSigSendType" ENUM "Cyclic","OnWrite","OnWriteWithRepetition","OnChange","OnChangeWithRepetition","IfActive","IfActiveWithRepetition","NoSigSendType";
BA_DEF_ SG_ "GenSigStartValue" HEX 0 80000000;
BA_DEF_ BO_ "GenMsgILSupport" ENUM "No","Yes";
BA_DEF_ BO_ "NmAsrMessage" ENUM "No","Yes";
BA_DEF_  "NmAsrBaseAddress" HEX 0 536870911;
BA_DEF_  "NmAsrMessageCount" INT 0 255;
BA_DEF_ BU_ "NodeLayerModules" STRING;
BA_DEF_ BU_ "ILused" ENUM "No","Yes";
BA_DEF_ SG_ "GenSigFuncType" ENUM "NoFunction","n/a","n/a","n/a","n/a","n/a","n/a","n/a","n/a","n/a","n/a","n/a","n/a","n/a","n/a","CHK","CNTR","n/a","n/a","n/a","CNTR_AR_01","CRC_AR_01_BOTH","CRC_AR_01_ALT","CRC_AR_01_LOW","CRC_AR_01_NIBBLE","CNTR_AR_04","CRC_AR_04A","CNTR_AR_05","CRC_AR_05";
BA_DEF_ SG_ "GenSigDataID" STRING;

BA_DEF_DEF_ "BusType" "";
BA_DEF_DEF_ "DBName" "";
BA_DEF_DEF_ "ProtocolType" "";
BA_DEF_DEF_ "NmAsrNode" "No";
BA_DEF_DEF_ "NmAsrNodeIdentifier" 0;
BA_DEF_DEF_ "CANFD_BRS" "1";
BA_DEF_DEF_ "GenSigStartValue" 0;
BA_DEF_DEF_ "VFrameFormat" "J1939PG";
BA_DEF_DEF_ "GenSigSendType" "NoSigSendType";
BA_DEF_DEF_ "GenMsgCycleTime" 0;
BA_DEF_DEF_ "GenMsgDelayTime" 0;
BA_DEF_DEF_ "GenMsgStartDelayTime" 0;
BA_DEF_DEF_ "GenMsgSendType" "NoMsgSendType";
BA_DEF_DEF_ "GenMsgILSupport" "Yes";
BA_DEF_DEF_ "NmAsrMessage" "No";
BA_DEF_DEF_ "NmAsrBaseAddress" 1280;
BA_DEF_DEF_ "NmAsrMessageCount" 64;
BA_DEF_DEF_ "NodeLayerModules" "CANoeILNLSPA.dll";
BA_DEF_DEF_ "ILused" "Yes";
BA_DEF_DEF_ "GenSigFuncType" "NoFunction";
BA_DEF_DEF_ "GenSigDataID" "";

BA_ "BaudRateCANFD" 2000000;
BA_ "Baudrate" 500000;
BA_ "BusType" "CAN FD";
BA_ "DBName" "Mid6CANFD";
BA_ "ProtocolType" "CAN";
// Network
// ECU: ETC
BA_ "ILused" BU_ ETC 0;
// ECU: SSMB
BA_ "NmAsrNode" BU_ SSMB 1;
BA_ "NmAsrNodeIdentifier" BU_ SSMB 12;
BA_ "NodeLayerModules" BU_ SSMB "CANoeILNLSPA.dll,AsrNM33.dll";
// ECU: VIMB
BA_ "NmAsrNode" BU_ VIMB 1;
BA_ "NmAsrNodeIdentifier" BU_ VIMB 10;
BA_ "NodeLayerModules" BU_ VIMB "CANoeILNLSPA.dll,AsrNM33.dll";
// Frame: SSMBMid6CanFdFr01
BA_ "GenMsgCycleTime" BO_ 23 10.000;
BA_ "GenMsgSendType" BO_ 23 0;
BA_ "VFrameFormat" BO_ 23 14;
// Frame: SSMBMid6CanFdFr02
BA_ "GenMsgCycleTime" BO_ 72 10.000;
BA_ "GenMsgSendType" BO_ 72 0;
BA_ "VFrameFormat" BO_ 72 14;
// Frame: SSMBMid6CanFdFr03
BA_ "GenMsgCycleTime" BO_ 259 80.000;
BA_ "GenMsgSendType" BO_ 259 0;
BA_ "VFrameFormat" BO_ 259 14;
// Frame: SSMBMid6CanFdFr04
BA_ "GenMsgCycleTime" BO_ 21 5.000;
BA_ "GenMsgSendType" BO_ 21 0;
BA_ "VFrameFormat" BO_ 21 14;
// Frame: SSMBMid6CanFdFr05
BA_ "GenMsgCycleTime" BO_ 32 10.000;
BA_ "GenMsgSendType" BO_ 32 0;
BA_ "VFrameFormat" BO_ 32 14;
// Frame: SSMBMid6CanFdFr06
BA_ "GenMsgCycleTime" BO_ 49 10.000;
BA_ "GenMsgSendType" BO_ 49 0;
BA_ "VFrameFormat" BO_ 49 14;
// Frame: SSMBMid6CanFdFr07
BA_ "GenMsgCycleTime" BO_ 122 40.000;
BA_ "GenMsgSendType" BO_ 122 0;
BA_ "VFrameFormat" BO_ 122 14;
// Frame: SSMBMid6CanFdFr08
BA_ "GenMsgCycleTime" BO_ 52 10.000;
BA_ "GenMsgSendType" BO_ 52 0;
BA_ "VFrameFormat" BO_ 52 14;
// Frame: SSMBMid6CanFdFr11
BA_ "GenMsgCycleTime" BO_ 85 25.000;
BA_ "GenMsgSendType" BO_ 85 0;
BA_ "VFrameFormat" BO_ 85 14;
// Frame: SsmbMid6CanFdCanNmFr
BA_ "GenMsgDelayTime" BO_ 1292 20.000;
BA_ "GenMsgSendType" BO_ 1292 1;
BA_ "VFrameFormat" BO_ 1292 0;
// Frame: VIMBMid6CanFdFr01
BA_ "GenMsgCycleTime" BO_ 256 65.000;
BA_ "GenMsgSendType" BO_ 256 0;
BA_ "VFrameFormat" BO_ 256 14;
// Frame: VIMBMid6CanFdFr03
BA_ "GenMsgCycleTime" BO_ 65 10.000;
BA_ "GenMsgSendType" BO_ 65 0;
BA_ "VFrameFormat" BO_ 65 14;
// Frame: VIMBMid6CanFdFr04
BA_ "GenMsgCycleTime" BO_ 144 60.000;
BA_ "GenMsgSendType" BO_ 144 0;
BA_ "VFrameFormat" BO_ 144 14;
// Frame: VIMBMid6CanFdFr14
BA_ "GenMsgCycleTime" BO_ 38 10.000;
BA_ "GenMsgSendType" BO_ 38 0;
BA_ "VFrameFormat" BO_ 38 14;
// Frame: VIMBMid6CanFdFr19
BA_ "GenMsgCycleTime" BO_ 272 90.000;
BA_ "GenMsgSendType" BO_ 272 0;
BA_ "VFrameFormat" BO_ 272 14;
// Frame: VIMBMid6CanFdFr20
BA_ "GenMsgCycleTime" BO_ 278 90.000;
BA_ "GenMsgSendType" BO_ 278 0;
BA_ "VFrameFormat" BO_ 278 14;
// Frame: VIMBMid6CanFdFr21
BA_ "GenMsgCycleTime" BO_ 281 90.000;
BA_ "GenMsgSendType" BO_ 281 0;
BA_ "VFrameFormat" BO_ 281 14;
// Frame: VimbMid6CanFdCanNmFr
BA_ "GenMsgDelayTime" BO_ 1290 20.000;
BA_ "GenMsgSendType" BO_ 1290 1;
BA_ "VFrameFormat" BO_ 1290 0;
BA_ "GenMsgILSupport" BO_ 1292 0;
BA_ "GenMsgILSupport" BO_ 1290 0;
BA_ "NmAsrMessage" BO_ 1292 1;
BA_ "NmAsrMessage" BO_ 1290 1;
BA_ "GenSigDataID" SG_ 72 AdSecMotTqASILThrshldExcdChks "0x728";
BA_ "GenSigFuncType" SG_ 72 AdSecMotTqASILThrshldExcdChks 15;
BA_ "GenSigFuncType" SG_ 72 AdSecMotTqASILThrshldExcdCntr 16;
BA_ "GenSigDataID" SG_ 272 AdSecPSSGroupSafe0Chks "0x2C1";
BA_ "GenSigFuncType" SG_ 272 AdSecPSSGroupSafe0Chks 28;
BA_ "GenSigFuncType" SG_ 272 AdSecPSSGroupSafe0Cntr 27;
BA_ "GenSigStartValue" SG_ 272 AdSecPSSGroupSafe0DeltaXPos1 131070;
BA_ "GenSigStartValue" SG_ 272 AdSecPSSGroupSafe0DeltaXPos2 131070;
BA_ "GenSigStartValue" SG_ 272 AdSecPSSGroupSafe0DeltaYPos1 131070;
BA_ "GenSigStartValue" SG_ 272 AdSecPSSGroupSafe0DeltaYPos2 131070;
BA_ "GenSigStartValue" SG_ 272 AdSecPSSGroupSafe0HeadingPos1 32767;
BA_ "GenSigStartValue" SG_ 272 AdSecPSSGroupSafe0HeadingPos2 32767;
BA_ "GenSigStartValue" SG_ 272 AdSecPSSGroupSafe0InitHeading 32767;
BA_ "GenSigDataID" SG_ 278 AdSecPSSGroupSafe1Chks "0x2C2";
BA_ "GenSigFuncType" SG_ 278 AdSecPSSGroupSafe1Chks 28;
BA_ "GenSigFuncType" SG_ 278 AdSecPSSGroupSafe1Cntr 27;
BA_ "GenSigStartValue" SG_ 278 AdSecPSSGroupSafe1DeltaXPos1 131070;
BA_ "GenSigStartValue" SG_ 278 AdSecPSSGroupSafe1DeltaXPos2 131070;
BA_ "GenSigStartValue" SG_ 278 AdSecPSSGroupSafe1DeltaXPos3 131070;
BA_ "GenSigStartValue" SG_ 278 AdSecPSSGroupSafe1DeltaXPos4 131070;
BA_ "GenSigStartValue" SG_ 278 AdSecPSSGroupSafe1DeltaXPos5 131070;
BA_ "GenSigStartValue" SG_ 278 AdSecPSSGroupSafe1DeltaXPos6 131070;
BA_ "GenSigStartValue" SG_ 278 AdSecPSSGroupSafe1DeltaYPos1 131070;
BA_ "GenSigStartValue" SG_ 278 AdSecPSSGroupSafe1DeltaYPos2 131070;
BA_ "GenSigStartValue" SG_ 278 AdSecPSSGroupSafe1DeltaYPos3 131070;
BA_ "GenSigStartValue" SG_ 278 AdSecPSSGroupSafe1DeltaYPos4 131070;
BA_ "GenSigStartValue" SG_ 278 AdSecPSSGroupSafe1DeltaYPos5 131070;
BA_ "GenSigStartValue" SG_ 278 AdSecPSSGroupSafe1DeltaYPos6 131070;
BA_ "GenSigStartValue" SG_ 278 AdSecPSSGroupSafe1HeadingPos1 32767;
BA_ "GenSigStartValue" SG_ 278 AdSecPSSGroupSafe1HeadingPos2 32767;
BA_ "GenSigStartValue" SG_ 278 AdSecPSSGroupSafe1HeadingPos3 32767;
BA_ "GenSigStartValue" SG_ 278 AdSecPSSGroupSafe1HeadingPos4 32767;
BA_ "GenSigStartValue" SG_ 278 AdSecPSSGroupSafe1HeadingPos5 32767;
BA_ "GenSigStartValue" SG_ 278 AdSecPSSGroupSafe1HeadingPos6 32767;
BA_ "GenSigDataID" SG_ 281 AdSecPSSGroupSafe2Chks "0x2C3";
BA_ "GenSigFuncType" SG_ 281 AdSecPSSGroupSafe2Chks 28;
BA_ "GenSigFuncType" SG_ 281 AdSecPSSGroupSafe2Cntr 27;
BA_ "GenSigStartValue" SG_ 281 AdSecPSSGroupSafe2DeltaXPos1 131070;
BA_ "GenSigStartValue" SG_ 281 AdSecPSSGroupSafe2DeltaXPos2 131070;
BA_ "GenSigStartValue" SG_ 281 AdSecPSSGroupSafe2DeltaXPos3 131070;
BA_ "GenSigStartValue" SG_ 281 AdSecPSSGroupSafe2DeltaXPos4 131070;
BA_ "GenSigStartValue" SG_ 281 AdSecPSSGroupSafe2DeltaXPos5 131070;
BA_ "GenSigStartValue" SG_ 281 AdSecPSSGroupSafe2DeltaXPos6 131070;
BA_ "GenSigStartValue" SG_ 281 AdSecPSSGroupSafe2DeltaYPos1 131070;
BA_ "GenSigStartValue" SG_ 281 AdSecPSSGroupSafe2DeltaYPos2 131070;
BA_ "GenSigStartValue" SG_ 281 AdSecPSSGroupSafe2DeltaYPos3 131070;
BA_ "GenSigStartValue" SG_ 281 AdSecPSSGroupSafe2DeltaYPos4 131070;
BA_ "GenSigStartValue" SG_ 281 AdSecPSSGroupSafe2DeltaYPos5 131070;
BA_ "GenSigStartValue" SG_ 281 AdSecPSSGroupSafe2DeltaYPos6 131070;
BA_ "GenSigStartValue" SG_ 281 AdSecPSSGroupSafe2HeadingPos1 32767;
BA_ "GenSigStartValue" SG_ 281 AdSecPSSGroupSafe2HeadingPos2 32767;
BA_ "GenSigStartValue" SG_ 281 AdSecPSSGroupSafe2HeadingPos3 32767;
BA_ "GenSigStartValue" SG_ 281 AdSecPSSGroupSafe2HeadingPos4 32767;
BA_ "GenSigStartValue" SG_ 281 AdSecPSSGroupSafe2HeadingPos5 32767;
BA_ "GenSigStartValue" SG_ 281 AdSecPSSGroupSafe2HeadingPos6 32767;
BA_ "GenSigStartValue" SG_ 65 AdSecPoseAX 524290;
BA_ "GenSigStartValue" SG_ 65 AdSecPoseAY 524290;
BA_ "GenSigStartValue" SG_ 65 AdSecPoseAZ 524290;
BA_ "GenSigDataID" SG_ 65 AdSecPoseChks "0x507";
BA_ "GenSigFuncType" SG_ 65 AdSecPoseChks 28;
BA_ "GenSigFuncType" SG_ 65 AdSecPoseCntr 27;
BA_ "GenSigStartValue" SG_ 65 AdSecPosePitch 32760;
BA_ "GenSigStartValue" SG_ 65 AdSecPosePitchRate 524300;
BA_ "GenSigStartValue" SG_ 65 AdSecPoseRoll 32760;
BA_ "GenSigStartValue" SG_ 65 AdSecPoseRollRate 524300;
BA_ "GenSigStartValue" SG_ 65 AdSecPoseVX 12768;
BA_ "GenSigStartValue" SG_ 65 AdSecPoseVY 8192;
BA_ "GenSigStartValue" SG_ 65 AdSecPoseYaw 8388000;
BA_ "GenSigStartValue" SG_ 65 AdSecPoseYawRate 2097000;
BA_ "GenSigDataID" SG_ 85 AdSecSafeStopActvGroupSafeChks "0x1EC";
BA_ "GenSigFuncType" SG_ 85 AdSecSafeStopActvGroupSafeChks 15;
BA_ "GenSigFuncType" SG_ 85 AdSecSafeStopActvGroupSafeCntr 16;
BA_ "GenSigDataID" SG_ 256 AdSecSafeStopReqSafeChks "0x203";
BA_ "GenSigFuncType" SG_ 256 AdSecSafeStopReqSafeChks 15;
BA_ "GenSigFuncType" SG_ 256 AdSecSafeStopReqSafeCntr 16;
BA_ "GenSigStartValue" SG_ 23 AdSecSteerStsSafeGroupAdSteerPerf 20;
BA_ "GenSigStartValue" SG_ 23 AdSecSteerStsSafeGroupAdSteerSts 4;
BA_ "GenSigDataID" SG_ 23 AdSecSteerStsSafeGroupChks "0x1A1";
BA_ "GenSigFuncType" SG_ 23 AdSecSteerStsSafeGroupChks 15;
BA_ "GenSigFuncType" SG_ 23 AdSecSteerStsSafeGroupCntr 16;
BA_ "GenSigDataID" SG_ 32 AdSecWhlAgEstimdGroupSafeChks "0x1B0";
BA_ "GenSigFuncType" SG_ 32 AdSecWhlAgEstimdGroupSafeChks 15;
BA_ "GenSigFuncType" SG_ 32 AdSecWhlAgEstimdGroupSafeCntr 16;
BA_ "GenSigStartValue" SG_ 32 AdSecWhlAgEstimdGroupSafeWhlAg 16193.5606782;
BA_ "GenSigStartValue" SG_ 32 AdSecWhlAgEstimdGroupSafeWhlAgRate 14000;
BA_ "GenSigStartValue" SG_ 85 AdSecWhlAgRateLimEstimdSafeAdWhlAgRate1 14000;
BA_ "GenSigDataID" SG_ 85 AdSecWhlAgRateLimEstimdSafeChks "0x435";
BA_ "GenSigFuncType" SG_ 85 AdSecWhlAgRateLimEstimdSafeChks 15;
BA_ "GenSigFuncType" SG_ 85 AdSecWhlAgRateLimEstimdSafeCntr 16;
BA_ "GenSigDataID" SG_ 38 AdSecWhlAgReqGroupSafeChks "0x1B1";
BA_ "GenSigFuncType" SG_ 38 AdSecWhlAgReqGroupSafeChks 15;
BA_ "GenSigFuncType" SG_ 38 AdSecWhlAgReqGroupSafeCntr 16;
BA_ "GenSigStartValue" SG_ 38 AdSecWhlAgReqGroupSafeWhlAgReq 16194.000762;
BA_ "GenSigDataID" SG_ 21 BrkDegradedRdntChks "0x255";
BA_ "GenSigFuncType" SG_ 21 BrkDegradedRdntChks 15;
BA_ "GenSigFuncType" SG_ 21 BrkDegradedRdntCntr 16;
BA_ "GenSigDataID" SG_ 256 SDSFltMgrStsRdntChks "0x735";
BA_ "GenSigFuncType" SG_ 256 SDSFltMgrStsRdntChks 15;
BA_ "GenSigFuncType" SG_ 256 SDSFltMgrStsRdntCntr 16;
BA_ "GenSigDataID" SG_ 49 SecALatDataRawSafeChks "0x214";
BA_ "GenSigFuncType" SG_ 49 SecALatDataRawSafeChks 15;
BA_ "GenSigFuncType" SG_ 49 SecALatDataRawSafeCntr 16;
BA_ "GenSigStartValue" SG_ 49 SecALatDataRawSafeMax 16384;
BA_ "GenSigStartValue" SG_ 49 SecALatDataRawSafeMin 16384;
BA_ "GenSigStartValue" SG_ 49 SecALatDataRawSafeNom 16384;
BA_ "GenSigStartValue" SG_ 49 SecALatDataRawSafeNomQf 1;
BA_ "GenSigDataID" SG_ 49 SecALgtDataRawSafeChks "0x217";
BA_ "GenSigFuncType" SG_ 49 SecALgtDataRawSafeChks 15;
BA_ "GenSigFuncType" SG_ 49 SecALgtDataRawSafeCntr 16;
BA_ "GenSigStartValue" SG_ 49 SecALgtDataRawSafeMax 16384;
BA_ "GenSigStartValue" SG_ 49 SecALgtDataRawSafeMin 16384;
BA_ "GenSigStartValue" SG_ 49 SecALgtDataRawSafeNom 16384;
BA_ "GenSigStartValue" SG_ 49 SecALgtDataRawSafeNomQf 1;
BA_ "GenSigStartValue" SG_ 49 SecAxleSlipStsAndRelAgFrntAxle 1;
BA_ "GenSigStartValue" SG_ 49 SecAxleSlipStsAndRelAgIntvSts 1;
BA_ "GenSigStartValue" SG_ 49 SecAxleSlipStsAndRelAgReAxle 1;
BA_ "GenSigStartValue" SG_ 49 SecAxleSlipStsAndRelAgRelPitchQf 1;
BA_ "GenSigStartValue" SG_ 49 SecAxleSlipStsAndRelAgRelRolQf 1;
BA_ "GenSigDataID" SG_ 259 SecPoseMonSafeChks "0x80C";
BA_ "GenSigFuncType" SG_ 259 SecPoseMonSafeChks 15;
BA_ "GenSigFuncType" SG_ 259 SecPoseMonSafeCntr 16;
BA_ "GenSigDataID" SG_ 144 SecRoadGradientlFromAdChks "0x1DD";
BA_ "GenSigFuncType" SG_ 144 SecRoadGradientlFromAdChks 15;
BA_ "GenSigFuncType" SG_ 144 SecRoadGradientlFromAdCntr 16;
BA_ "GenSigStartValue" SG_ 259 SecSteerMotTqSteerMotTqQf 1;
BA_ "GenSigDataID" SG_ 49 SecVLatSafeChks "0x506";
BA_ "GenSigFuncType" SG_ 49 SecVLatSafeChks 15;
BA_ "GenSigFuncType" SG_ 49 SecVLatSafeCntr 16;
BA_ "GenSigStartValue" SG_ 49 SecVLatSafeNomQf 1;
BA_ "GenSigDataID" SG_ 52 SecVehMSafeChks "0x726";
BA_ "GenSigFuncType" SG_ 52 SecVehMSafeChks 15;
BA_ "GenSigFuncType" SG_ 52 SecVehMSafeCntr 16;
BA_ "GenSigStartValue" SG_ 52 SecVehMSafeNomQf 1;
BA_ "GenSigDataID" SG_ 122 SecVehSpdGroupSafeChks "0x218";
BA_ "GenSigFuncType" SG_ 122 SecVehSpdGroupSafeChks 15;
BA_ "GenSigFuncType" SG_ 122 SecVehSpdGroupSafeCntr 16;
BA_ "GenSigStartValue" SG_ 122 SecVehSpdGroupSafeNomQf 1;
BA_ "GenSigDataID" SG_ 52 SecWhlAgSpdFrntSafeChks "0x1E6";
BA_ "GenSigFuncType" SG_ 52 SecWhlAgSpdFrntSafeChks 15;
BA_ "GenSigFuncType" SG_ 52 SecWhlAgSpdFrntSafeCntr 16;
BA_ "GenSigStartValue" SG_ 52 SecWhlAgSpdFrntSafeLeQf 1;
BA_ "GenSigStartValue" SG_ 52 SecWhlAgSpdFrntSafeRiQf 1;
BA_ "GenSigDataID" SG_ 52 SecWhlAgSpdReSafeChks "0x1E5";
BA_ "GenSigFuncType" SG_ 52 SecWhlAgSpdReSafeChks 15;
BA_ "GenSigFuncType" SG_ 52 SecWhlAgSpdReSafeCntr 16;
BA_ "GenSigStartValue" SG_ 52 SecWhlAgSpdReSafeLeQf 1;
BA_ "GenSigStartValue" SG_ 52 SecWhlAgSpdReSafeRiQf 1;
BA_ "GenSigDataID" SG_ 259 SecWhlLockStsChks "0x80F";
BA_ "GenSigFuncType" SG_ 259 SecWhlLockStsChks 15;
BA_ "GenSigFuncType" SG_ 259 SecWhlLockStsCntr 16;
BA_ "GenSigDataID" SG_ 49 SecWhlRotDirReSafeChks "0x646";
BA_ "GenSigFuncType" SG_ 49 SecWhlRotDirReSafeChks 15;
BA_ "GenSigFuncType" SG_ 49 SecWhlRotDirReSafeCntr 16;
BA_ "GenSigStartValue" SG_ 49 SecWhlRotDirReSafeLeQf 1;
BA_ "GenSigStartValue" SG_ 49 SecWhlRotDirReSafeRiQf 1;
BA_ "GenSigDataID" SG_ 32 SecWhlRotToothCntrChks "0x579";
BA_ "GenSigFuncType" SG_ 32 SecWhlRotToothCntrChks 15;
BA_ "GenSigFuncType" SG_ 32 SecWhlRotToothCntrCntr 16;
BA_ "GenSigStartValue" SG_ 32 SecWhlRotToothCntrWhlRotToothCntrFrntLeQf 1;
BA_ "GenSigStartValue" SG_ 32 SecWhlRotToothCntrWhlRotToothCntrFrntRiQf 1;
BA_ "GenSigStartValue" SG_ 32 SecWhlRotToothCntrWhlRotToothCntrReLeQf 1;
BA_ "GenSigStartValue" SG_ 32 SecWhlRotToothCntrWhlRotToothCntrReRiQf 1;
BA_ "GenSigDataID" SG_ 49 SecYawRateSafeChks "0x215";
BA_ "GenSigFuncType" SG_ 49 SecYawRateSafeChks 15;
BA_ "GenSigFuncType" SG_ 49 SecYawRateSafeCntr 16;
BA_ "GenSigStartValue" SG_ 49 SecYawRateSafeNomQf 1;

VAL_ 23 AdSecSteerStsSafeGroupAdSteerPerf 0 "AdSteerPerf_PerfLvl0" 1 "AdSteerPerf_PerfLvl1" 2 "AdSteerPerf_PerfLvl2" 3 "AdSteerPerf_PerfLvl3" 4 "AdSteerPerf_PerfLvl4" 5 "AdSteerPerf_PerfLvl5" 6 "AdSteerPerf_PerfLvl6" 7 "AdSteerPerf_PerfLvl7" 8 "AdSteerPerf_PerfLvl8" 9 "AdSteerPerf_PerfLvl9" 10 "AdSteerPerf_PerfLvl10" 11 "AdSteerPerf_PerfLvl11" 12 "AdSteerPerf_PerfLvl12" 13 "AdSteerPerf_PerfLvl13" 14 "AdSteerPerf_PerfLvl14" 15 "AdSteerPerf_PerfLvl15" 16 "AdSteerPerf_PerfLvl16" 17 "AdSteerPerf_PerfLvl17" 18 "AdSteerPerf_PerfLvl18" 19 "AdSteerPerf_PerfLvl19" 20 "AdSteerPerf_PerfLvl20";
VAL_ 23 AdSecSteerStsSafeGroupAdSteerSts 0 "AdSteerSts_DegradedLvl4" 1 "AdSteerSts_DegradedLvl3" 2 "AdSteerSts_DegradedLvl2" 3 "AdSteerSts_DegradedLvl1" 4 "AdSteerSts_SysOK";
VAL_ 72 AdSecMotTqASILThrshldExcdThrshldExceeded 0 "OnOff1_Off" 1 "OnOff1_On";
VAL_ 259 SecPoseMonSafeSafeQf 0 "SafeQf_Ukwn" 1 "SafeQf_NoIntgrty" 2 "SafeQf_IntgrtyCmprmd" 3 "SafeQf_DataIntgrtyOK";
VAL_ 259 SecSteerMotTqSteerMotTqQf 0 "GenQf1_UndefindDataAccur" 1 "GenQf1_TmpUndefdData" 2 "GenQf1_DataAccurNotWithinSpcn" 3 "GenQf1_AccurData";
VAL_ 259 SecWhlLockStsDegradedSts 0 "WhlLockDegraded1_Ukwn" 1 "WhlLockDegraded1_FullFcn" 2 "WhlLockDegraded1_DegradedFcn" 3 "WhlLockDegraded1_NoFcn";
VAL_ 259 SecWhlLockStsLockSts 0 "WhlLockSts1_Ukwn" 1 "WhlLockSts1_AllWhlsReld" 2 "WhlLockSts1_FrntWhlsLockd" 3 "WhlLockSts1_ReWhlsLockd" 4 "WhlLockSts1_AllWhlsLockd";
VAL_ 259 SSMBDegradedSSMBDegraded 0 "SSMBDegraded_SftyCritFlt" 1 "SSMBDegraded_SftyCritLatentFlt" 2 "SSMBDegraded_PSSFlt" 3 "SSMBDegraded_NonSftyCritFlt" 4 "SSMBDegraded_NoFlt";
VAL_ 32 AdSecWhlAgEstimdGroupSafeQf1 0 "Qf1_DevOfDataUndefd" 1 "Qf1_DataTmpUndefdAndEvlnInProgs" 2 "Qf1_DevOfDataNotWithinRngAllwd" 3 "Qf1_DataCalcdWithDevDefd";
VAL_ 32 SecWhlRotToothCntrWhlRotToothCntrFrntLeQf 0 "GenQf1_UndefindDataAccur" 1 "GenQf1_TmpUndefdData" 2 "GenQf1_DataAccurNotWithinSpcn" 3 "GenQf1_AccurData";
VAL_ 32 SecWhlRotToothCntrWhlRotToothCntrFrntRiQf 0 "GenQf1_UndefindDataAccur" 1 "GenQf1_TmpUndefdData" 2 "GenQf1_DataAccurNotWithinSpcn" 3 "GenQf1_AccurData";
VAL_ 32 SecWhlRotToothCntrWhlRotToothCntrReLeQf 0 "GenQf1_UndefindDataAccur" 1 "GenQf1_TmpUndefdData" 2 "GenQf1_DataAccurNotWithinSpcn" 3 "GenQf1_AccurData";
VAL_ 32 SecWhlRotToothCntrWhlRotToothCntrReRiQf 0 "GenQf1_UndefindDataAccur" 1 "GenQf1_TmpUndefdData" 2 "GenQf1_DataAccurNotWithinSpcn" 3 "GenQf1_AccurData";
VAL_ 49 SecALatDataRawSafeMinMaxQf 0 "SafeQf_Ukwn" 1 "SafeQf_NoIntgrty" 2 "SafeQf_IntgrtyCmprmd" 3 "SafeQf_DataIntgrtyOK";
VAL_ 49 SecALatDataRawSafeNomQf 0 "GenQf1_UndefindDataAccur" 1 "GenQf1_TmpUndefdData" 2 "GenQf1_DataAccurNotWithinSpcn" 3 "GenQf1_AccurData";
VAL_ 49 SecALgtDataRawSafeMinMaxQf 0 "SafeQf_Ukwn" 1 "SafeQf_NoIntgrty" 2 "SafeQf_IntgrtyCmprmd" 3 "SafeQf_DataIntgrtyOK";
VAL_ 49 SecALgtDataRawSafeNomQf 0 "GenQf1_UndefindDataAccur" 1 "GenQf1_TmpUndefdData" 2 "GenQf1_DataAccurNotWithinSpcn" 3 "GenQf1_AccurData";
VAL_ 49 SecAxleSlipStsAndRelAgFrntAxle 0 "SlipSts_Err" 1 "SlipSts_NoInfo" 2 "SlipSts_NotSlip" 3 "SlipSts_Slip";
VAL_ 49 SecAxleSlipStsAndRelAgIntvSts 0 "IntvSts_Err" 1 "IntvSts_NoInfo" 2 "IntvSts_NoIntv" 3 "IntvSts_Intv";
VAL_ 49 SecAxleSlipStsAndRelAgReAxle 0 "SlipSts_Err" 1 "SlipSts_NoInfo" 2 "SlipSts_NotSlip" 3 "SlipSts_Slip";
VAL_ 49 SecAxleSlipStsAndRelAgRelPitchQf 0 "Qly2_Flt" 1 "Qly2_NoInfo" 2 "Qly2_Vld";
VAL_ 49 SecAxleSlipStsAndRelAgRelRolQf 0 "Qly2_Flt" 1 "Qly2_NoInfo" 2 "Qly2_Vld";
VAL_ 49 SecVLatSafeMinMaxQf 0 "SafeQf_Ukwn" 1 "SafeQf_NoIntgrty" 2 "SafeQf_IntgrtyCmprmd" 3 "SafeQf_DataIntgrtyOK";
VAL_ 49 SecVLatSafeNomQf 0 "GenQf1_UndefindDataAccur" 1 "GenQf1_TmpUndefdData" 2 "GenQf1_DataAccurNotWithinSpcn" 3 "GenQf1_AccurData";
VAL_ 49 SecWhlRotDirReSafeLe 0 "WhlRotlDirStd1_Undefd" 1 "WhlRotlDirStd1_StandStill" 2 "WhlRotlDirStd1_Fwd" 3 "WhlRotlDirStd1_Backw";
VAL_ 49 SecWhlRotDirReSafeLeQf 0 "Qf1_DevOfDataUndefd" 1 "Qf1_DataTmpUndefdAndEvlnInProgs" 2 "Qf1_DevOfDataNotWithinRngAllwd" 3 "Qf1_DataCalcdWithDevDefd";
VAL_ 49 SecWhlRotDirReSafeRi 0 "WhlRotlDirStd1_Undefd" 1 "WhlRotlDirStd1_StandStill" 2 "WhlRotlDirStd1_Fwd" 3 "WhlRotlDirStd1_Backw";
VAL_ 49 SecWhlRotDirReSafeRiQf 0 "Qf1_DevOfDataUndefd" 1 "Qf1_DataTmpUndefdAndEvlnInProgs" 2 "Qf1_DevOfDataNotWithinRngAllwd" 3 "Qf1_DataCalcdWithDevDefd";
VAL_ 49 SecYawRateSafeMinMaxQf 0 "SafeQf_Ukwn" 1 "SafeQf_NoIntgrty" 2 "SafeQf_IntgrtyCmprmd" 3 "SafeQf_DataIntgrtyOK";
VAL_ 49 SecYawRateSafeNomQf 0 "GenQf1_UndefindDataAccur" 1 "GenQf1_TmpUndefdData" 2 "GenQf1_DataAccurNotWithinSpcn" 3 "GenQf1_AccurData";
VAL_ 122 SecVehSpdGroupSafeMinMaxQf 0 "SafeQf_Ukwn" 1 "SafeQf_NoIntgrty" 2 "SafeQf_IntgrtyCmprmd" 3 "SafeQf_DataIntgrtyOK";
VAL_ 122 SecVehSpdGroupSafeMovDir 0 "MovDir1_Ukwn" 1 "MovDir1_Standstill" 2 "MovDir1_NotStandstill" 3 "MovDir1_Fwd" 4 "MovDir1_Rvs" 5 "MovDir1_Err";
VAL_ 122 SecVehSpdGroupSafeMovDirQf 0 "SafeQf_Ukwn" 1 "SafeQf_NoIntgrty" 2 "SafeQf_IntgrtyCmprmd" 3 "SafeQf_DataIntgrtyOK";
VAL_ 122 SecVehSpdGroupSafeNomQf 0 "GenQf1_UndefindDataAccur" 1 "GenQf1_TmpUndefdData" 2 "GenQf1_DataAccurNotWithinSpcn" 3 "GenQf1_AccurData";
VAL_ 52 SecVehMSafeNomQf 0 "GenQf1_UndefindDataAccur" 1 "GenQf1_TmpUndefdData" 2 "GenQf1_DataAccurNotWithinSpcn" 3 "GenQf1_AccurData";
VAL_ 52 SecVehMSafeSafeQf 0 "SafeQf_Ukwn" 1 "SafeQf_NoIntgrty" 2 "SafeQf_IntgrtyCmprmd" 3 "SafeQf_DataIntgrtyOK";
VAL_ 52 SecWhlAgSpdFrntSafeLeQf 0 "GenQf1_UndefindDataAccur" 1 "GenQf1_TmpUndefdData" 2 "GenQf1_DataAccurNotWithinSpcn" 3 "GenQf1_AccurData";
VAL_ 52 SecWhlAgSpdFrntSafeRiQf 0 "GenQf1_UndefindDataAccur" 1 "GenQf1_TmpUndefdData" 2 "GenQf1_DataAccurNotWithinSpcn" 3 "GenQf1_AccurData";
VAL_ 52 SecWhlAgSpdReSafeLeQf 0 "GenQf1_UndefindDataAccur" 1 "GenQf1_TmpUndefdData" 2 "GenQf1_DataAccurNotWithinSpcn" 3 "GenQf1_AccurData";
VAL_ 52 SecWhlAgSpdReSafeRiQf 0 "GenQf1_UndefindDataAccur" 1 "GenQf1_TmpUndefdData" 2 "GenQf1_DataAccurNotWithinSpcn" 3 "GenQf1_AccurData";
VAL_ 85 AdSecSafeStopActvGroupSafePlatformSafeStopActv 0 "NoYes1_No" 1 "NoYes1_Yes";
VAL_ 256 AdSecSafeStopReqSafeSafeStopReq 0 "NoYes1_No" 1 "NoYes1_Yes";
VAL_ 256 SDSFltMgrStsRdntSDSFltMgrStsRdnt 0 "SDSFltMgrStsRdnt_Nom" 1 "SDSFltMgrStsRdnt_Resd" 2 "SDSFltMgrStsRdnt_Mntn" 3 "SDSFltMgrStsRdnt_Resd1" 4 "SDSFltMgrStsRdnt_CmptRtrn" 5 "SDSFltMgrStsRdnt_Resd2" 6 "SDSFltMgrStsRdnt_SS" 7 "SDSFltMgrStsRdnt_Resd3" 8 "SDSFltMgrStsRdnt_SS1" 9 "SDSFltMgrStsRdnt_Resd4" 10 "SDSFltMgrStsRdnt_VIMSS" 11 "SDSFltMgrStsRdnt_Resd5";
VAL_ 144 SecRoadGradientlFromAdBankingConf 0 "Qly3_De0" 1 "Qly3_De1" 2 "Qly3_De2" 3 "Qly3_De3" 4 "Qly3_De4" 5 "Qly3_De5" 6 "Qly3_De6" 7 "Qly3_De7";
VAL_ 144 SecRoadGradientlFromAdInclnConf 0 "Qly3_De0" 1 "Qly3_De1" 2 "Qly3_De2" 3 "Qly3_De3" 4 "Qly3_De4" 5 "Qly3_De5" 6 "Qly3_De6" 7 "Qly3_De7";
SIG_GROUP_ 72 AdSecMotTqASILThrshldExcd 1 : AdSecMotTqASILThrshldExcdChks AdSecMotTqASILThrshldExcdCntr AdSecMotTqASILThrshldExcdThrshldExceeded;
SIG_GROUP_ 65 AdSecPose 1 : AdSecPoseAX AdSecPoseAXConf AdSecPoseAY AdSecPoseAYConf AdSecPoseAZ AdSecPoseAZConf AdSecPoseChks AdSecPoseCntr AdSecPoseDataID AdSecPosePitch AdSecPosePitchConf AdSecPosePitchRate AdSecPosePitchRateConf AdSecPosePosX AdSecPosePosXConf AdSecPosePosY AdSecPosePosYConf AdSecPoseRoll AdSecPoseRollConf AdSecPoseRollRate AdSecPoseRollRateConf AdSecPoseTiStampNanoSec AdSecPoseTiStampSec AdSecPoseVX AdSecPoseVXConf AdSecPoseVY AdSecPoseVYConf AdSecPoseYaw AdSecPoseYawConf AdSecPoseYawRate AdSecPoseYawRateConf;
SIG_GROUP_ 272 AdSecPSSGroupSafe0 1 : AdSecPSSGroupSafe0Chks AdSecPSSGroupSafe0Cntr AdSecPSSGroupSafe0DataID AdSecPSSGroupSafe0DeltaTPos1 AdSecPSSGroupSafe0DeltaTPos2 AdSecPSSGroupSafe0DeltaXPos1 AdSecPSSGroupSafe0DeltaXPos2 AdSecPSSGroupSafe0DeltaYPos1 AdSecPSSGroupSafe0DeltaYPos2 AdSecPSSGroupSafe0HeadingPos1 AdSecPSSGroupSafe0HeadingPos2 AdSecPSSGroupSafe0InitHeading AdSecPSSGroupSafe0InitPosX AdSecPSSGroupSafe0InitPosY AdSecPSSGroupSafe0TiStampNanoSec AdSecPSSGroupSafe0TiStampSec AdSecPSSGroupSafe0TrajectID;
SIG_GROUP_ 278 AdSecPSSGroupSafe1 1 : AdSecPSSGroupSafe1Chks AdSecPSSGroupSafe1Cntr AdSecPSSGroupSafe1DataID AdSecPSSGroupSafe1DeltaTPos1 AdSecPSSGroupSafe1DeltaTPos2 AdSecPSSGroupSafe1DeltaTPos3 AdSecPSSGroupSafe1DeltaTPos4 AdSecPSSGroupSafe1DeltaTPos5 AdSecPSSGroupSafe1DeltaTPos6 AdSecPSSGroupSafe1DeltaXPos1 AdSecPSSGroupSafe1DeltaXPos2 AdSecPSSGroupSafe1DeltaXPos3 AdSecPSSGroupSafe1DeltaXPos4 AdSecPSSGroupSafe1DeltaXPos5 AdSecPSSGroupSafe1DeltaXPos6 AdSecPSSGroupSafe1DeltaYPos1 AdSecPSSGroupSafe1DeltaYPos2 AdSecPSSGroupSafe1DeltaYPos3 AdSecPSSGroupSafe1DeltaYPos4 AdSecPSSGroupSafe1DeltaYPos5 AdSecPSSGroupSafe1DeltaYPos6 AdSecPSSGroupSafe1HeadingPos1 AdSecPSSGroupSafe1HeadingPos2 AdSecPSSGroupSafe1HeadingPos3 AdSecPSSGroupSafe1HeadingPos4 AdSecPSSGroupSafe1HeadingPos5 AdSecPSSGroupSafe1HeadingPos6 AdSecPSSGroupSafe1TrajectID;
SIG_GROUP_ 281 AdSecPSSGroupSafe2 1 : AdSecPSSGroupSafe2Chks AdSecPSSGroupSafe2Cntr AdSecPSSGroupSafe2DataID AdSecPSSGroupSafe2DeltaTPos1 AdSecPSSGroupSafe2DeltaTPos2 AdSecPSSGroupSafe2DeltaTPos3 AdSecPSSGroupSafe2DeltaTPos4 AdSecPSSGroupSafe2DeltaTPos5 AdSecPSSGroupSafe2DeltaTPos6 AdSecPSSGroupSafe2DeltaXPos1 AdSecPSSGroupSafe2DeltaXPos2 AdSecPSSGroupSafe2DeltaXPos3 AdSecPSSGroupSafe2DeltaXPos4 AdSecPSSGroupSafe2DeltaXPos5 AdSecPSSGroupSafe2DeltaXPos6 AdSecPSSGroupSafe2DeltaYPos1 AdSecPSSGroupSafe2DeltaYPos2 AdSecPSSGroupSafe2DeltaYPos3 AdSecPSSGroupSafe2DeltaYPos4 AdSecPSSGroupSafe2DeltaYPos5 AdSecPSSGroupSafe2DeltaYPos6 AdSecPSSGroupSafe2HeadingPos1 AdSecPSSGroupSafe2HeadingPos2 AdSecPSSGroupSafe2HeadingPos3 AdSecPSSGroupSafe2HeadingPos4 AdSecPSSGroupSafe2HeadingPos5 AdSecPSSGroupSafe2HeadingPos6 AdSecPSSGroupSafe2TrajectID;
SIG_GROUP_ 85 AdSecSafeStopActvGroupSafe 1 : AdSecSafeStopActvGroupSafeChks AdSecSafeStopActvGroupSafeCntr AdSecSafeStopActvGroupSafePlatformSafeStopActv;
SIG_GROUP_ 256 AdSecSafeStopReqSafe 1 : AdSecSafeStopReqSafeChks AdSecSafeStopReqSafeCntr AdSecSafeStopReqSafeSafeStopReq;
SIG_GROUP_ 23 AdSecSteerStsSafeGroup 1 : AdSecSteerStsSafeGroupAdSteerPerf AdSecSteerStsSafeGroupAdSteerSts AdSecSteerStsSafeGroupChks AdSecSteerStsSafeGroupCntr;
SIG_GROUP_ 32 AdSecWhlAgEstimdGroupSafe 1 : AdSecWhlAgEstimdGroupSafeChks AdSecWhlAgEstimdGroupSafeCntr AdSecWhlAgEstimdGroupSafeQf1 AdSecWhlAgEstimdGroupSafeWhlAg AdSecWhlAgEstimdGroupSafeWhlAgRate;
SIG_GROUP_ 85 AdSecWhlAgRateLimEstimdSafe 1 : AdSecWhlAgRateLimEstimdSafeAdWhlAgRate1 AdSecWhlAgRateLimEstimdSafeChks AdSecWhlAgRateLimEstimdSafeCntr;
SIG_GROUP_ 38 AdSecWhlAgReqGroupSafe 1 : AdSecWhlAgReqGroupSafeChks AdSecWhlAgReqGroupSafeCntr AdSecWhlAgReqGroupSafeWhlAgReq;
SIG_GROUP_ 21 BrkDegradedRdnt 1 : BrkDegradedRdntChks BrkDegradedRdntCntr BrkDegradedRdntSts;
SIG_GROUP_ 256 SDSFltMgrStsRdnt 1 : SDSFltMgrStsRdntChks SDSFltMgrStsRdntCntr SDSFltMgrStsRdntSDSFltMgrStsRdnt;
SIG_GROUP_ 49 SecALatDataRawSafe 1 : SecALatDataRawSafeChks SecALatDataRawSafeCntr SecALatDataRawSafeMax SecALatDataRawSafeMin SecALatDataRawSafeMinMaxQf SecALatDataRawSafeNom SecALatDataRawSafeNomQf;
SIG_GROUP_ 49 SecALgtDataRawSafe 1 : SecALgtDataRawSafeChks SecALgtDataRawSafeCntr SecALgtDataRawSafeMax SecALgtDataRawSafeMin SecALgtDataRawSafeMinMaxQf SecALgtDataRawSafeNom SecALgtDataRawSafeNomQf;
SIG_GROUP_ 49 SecAxleSlipStsAndRelAg 1 : SecAxleSlipStsAndRelAgFrntAxle SecAxleSlipStsAndRelAgIntvSts SecAxleSlipStsAndRelAgReAxle SecAxleSlipStsAndRelAgRelPitch SecAxleSlipStsAndRelAgRelPitchQf SecAxleSlipStsAndRelAgRelRoll SecAxleSlipStsAndRelAgRelRolQf;
SIG_GROUP_ 85 SecMaxALatEstimdGroup 1 : SecMaxALatEstimdGroupAcceleration SecMaxALatEstimdGroupJerk;
SIG_GROUP_ 259 SecPoseMonSafe 1 : SecPoseMonSafeChks SecPoseMonSafeCntr SecPoseMonSafeLatErr SecPoseMonSafeLgtErr SecPoseMonSafeSafeQf SecPoseMonSafeYawErr;
SIG_GROUP_ 144 SecRoadGradientlFromAd 1 : SecRoadGradientlFromAdBanking SecRoadGradientlFromAdBankingConf SecRoadGradientlFromAdChks SecRoadGradientlFromAdCntr SecRoadGradientlFromAdIncln SecRoadGradientlFromAdInclnConf;
SIG_GROUP_ 259 SecSteerMotTq 1 : SecSteerMotTqSteerMotTq SecSteerMotTqSteerMotTqQf;
SIG_GROUP_ 52 SecVehMSafe 1 : SecVehMSafeChks SecVehMSafeCntr SecVehMSafeNomQf SecVehMSafeSafeQf SecVehMSafeVehMMax SecVehMSafeVehMMin SecVehMSafeVehMNom;
SIG_GROUP_ 122 SecVehSpdGroupSafe 1 : SecVehSpdGroupSafeChks SecVehSpdGroupSafeCntr SecVehSpdGroupSafeMax SecVehSpdGroupSafeMin SecVehSpdGroupSafeMinMaxQf SecVehSpdGroupSafeMovDir SecVehSpdGroupSafeMovDirQf SecVehSpdGroupSafeNom SecVehSpdGroupSafeNomQf;
SIG_GROUP_ 49 SecVLatSafe 1 : SecVLatSafeChks SecVLatSafeCntr SecVLatSafeMax SecVLatSafeMin SecVLatSafeMinMaxQf SecVLatSafeNom SecVLatSafeNomQf;
SIG_GROUP_ 52 SecWhlAgSpdFrntSafe 1 : SecWhlAgSpdFrntSafeChks SecWhlAgSpdFrntSafeCntr SecWhlAgSpdFrntSafeLe SecWhlAgSpdFrntSafeLeQf SecWhlAgSpdFrntSafeRi SecWhlAgSpdFrntSafeRiQf;
SIG_GROUP_ 52 SecWhlAgSpdReSafe 1 : SecWhlAgSpdReSafeChks SecWhlAgSpdReSafeCntr SecWhlAgSpdReSafeLe SecWhlAgSpdReSafeLeQf SecWhlAgSpdReSafeRi SecWhlAgSpdReSafeRiQf;
SIG_GROUP_ 259 SecWhlLockSts 1 : SecWhlLockStsChks SecWhlLockStsCntr SecWhlLockStsDegradedSts SecWhlLockStsLockSts;
SIG_GROUP_ 49 SecWhlRotDirReSafe 1 : SecWhlRotDirReSafeChks SecWhlRotDirReSafeCntr SecWhlRotDirReSafeLe SecWhlRotDirReSafeLeQf SecWhlRotDirReSafeRi SecWhlRotDirReSafeRiQf;
SIG_GROUP_ 32 SecWhlRotToothCntr 1 : SecWhlRotToothCntrChks SecWhlRotToothCntrCntr SecWhlRotToothCntrWhlRotToothCntrFrntLe SecWhlRotToothCntrWhlRotToothCntrFrntLeQf SecWhlRotToothCntrWhlRotToothCntrFrntRi SecWhlRotToothCntrWhlRotToothCntrFrntRiQf SecWhlRotToothCntrWhlRotToothCntrReLe SecWhlRotToothCntrWhlRotToothCntrReLeQf SecWhlRotToothCntrWhlRotToothCntrReRi SecWhlRotToothCntrWhlRotToothCntrReRiQf;
SIG_GROUP_ 49 SecYawRateSafe 1 : SecYawRateSafeChks SecYawRateSafeCntr SecYawRateSafeMax SecYawRateSafeMin SecYawRateSafeMinMaxQf SecYawRateSafeNom SecYawRateSafeNomQf;
SIG_GROUP_ 259 SSMBDegraded 1 : SSMBDegradedchks SSMBDegradedcntr SSMBDegradedSSMBDegraded;
